VERSION ""

NS_ :

BS_:

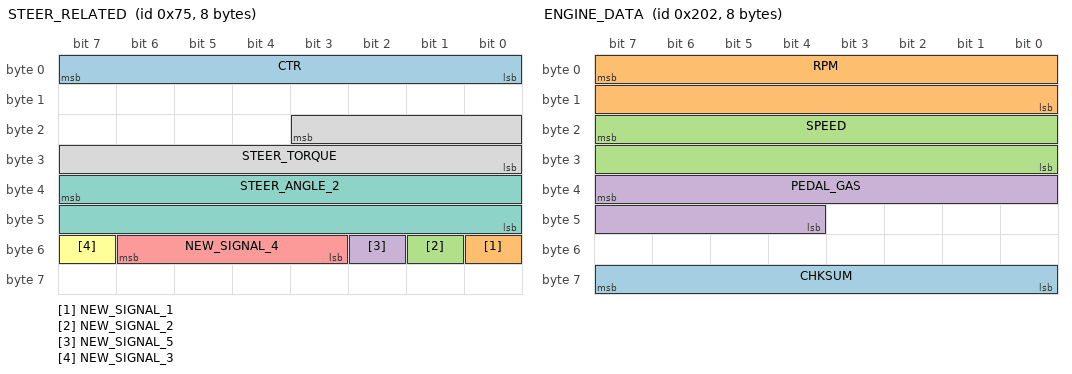
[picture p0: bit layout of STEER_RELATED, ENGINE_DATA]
BO_ 117 STEER_RELATED: 8 XXX
 SG_ CTR : 7|8@0+ (1,0) [0|255] "" XXX
 SG_ NEW_SIGNAL_1 : 48|1@0+ (1,0) [0|1] "" XXX
 SG_ NEW_SIGNAL_2 : 49|1@0+ (1,0) [0|1] "" XXX
 SG_ NEW_SIGNAL_5 : 50|1@0+ (1,0) [0|1] "" XXX
 SG_ NEW_SIGNAL_4 : 54|4@0+ (1,0) [0|31] "" XXX
 SG_ NEW_SIGNAL_3 : 55|1@0+ (1,0) [0|63] "" XXX
 SG_ STEER_ANGLE_2 : 39|16@0+ (0.1,-1800) [0|131071] "" XXX
 SG_ STEER_TORQUE : 19|12@0+ (1,-2000) [0|255] "" XXX

BO_ 118 RPM_RELATED: 8 XXX
 SG_ CTR : 7|8@0+ (1,0) [0|127] "" XXX
 SG_ NEW_SIGNAL_2 : 19|12@0+ (1,0) [0|4095] "" XXX

BO_ 514 ENGINE_DATA: 8 XXX
 SG_ CHKSUM : 63|8@0+ (1,0) [0|127] "" XXX
 SG_ RPM : 7|16@0+ (0.25,0) [0|8500] "rpm" XXX
 SG_ SPEED : 23|16@0+ (0.01,0) [0|32767] "kph" XXX
 SG_ PEDAL_GAS : 39|12@0+ (1,0) [0|255] "%" XXX

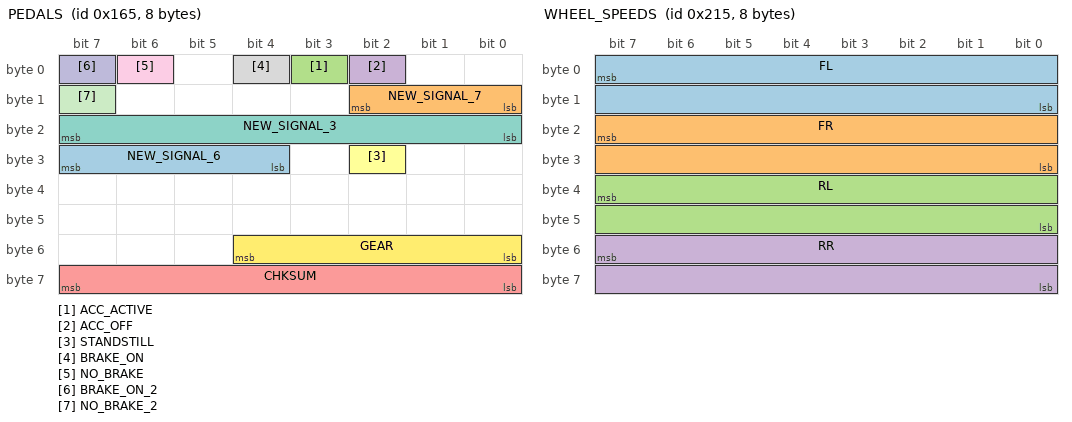
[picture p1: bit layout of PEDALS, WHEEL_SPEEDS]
BO_ 357 PEDALS: 8 XXX
 SG_ NEW_SIGNAL_6 : 31|4@0+ (1,0) [0|1] "" XXX
 SG_ NEW_SIGNAL_7 : 8|3@1+ (1,0) [0|7] "" XXX
 SG_ ACC_ACTIVE : 3|1@0+ (1,0) [0|1] "" XXX
 SG_ ACC_OFF : 2|1@1+ (1,0) [0|15] "" XXX
 SG_ CHKSUM : 63|8@0+ (1,0) [0|15] "" XXX
 SG_ STANDSTILL : 26|1@0+ (1,0) [0|16777215] "" XXX
 SG_ NEW_SIGNAL_3 : 23|8@0+ (1,0) [0|3] "" XXX
 SG_ BRAKE_ON : 4|1@0+ (1,0) [0|1] "" XXX
 SG_ NO_BRAKE : 6|1@0+ (1,0) [0|7] "" XXX
 SG_ BRAKE_ON_2 : 7|1@1+ (1,0) [0|255] "" XXX
 SG_ NO_BRAKE_2 : 15|1@0+ (1,0) [0|7] "" XXX
 SG_ GEAR : 48|5@1+ (1,0) [0|255] "" XXX

BO_ 533 WHEEL_SPEEDS: 8 XXX
 SG_ FL : 7|16@0+ (0.01,-100) [0|16383] "kph" XXX
 SG_ FR : 23|16@0+ (0.01,-100) [0|65535] "kph" XXX
 SG_ RL : 39|16@0+ (0.01,-100) [0|15] "kph" XXX
 SG_ RR : 55|16@0+ (0.01,-100) [0|65535] "kph" XXX

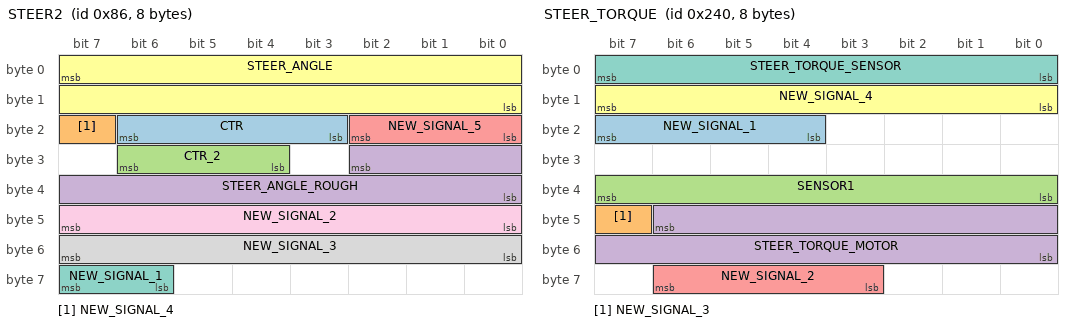
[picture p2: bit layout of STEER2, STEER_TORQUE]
BO_ 134 STEER2: 8 XXX
 SG_ CTR : 22|4@0+ (1,0) [0|7] "" XXX
 SG_ NEW_SIGNAL_4 : 23|1@0+ (1,0) [0|1] "" XXX
 SG_ CTR_2 : 28|3@1+ (1,0) [0|7] "" XXX
 SG_ STEER_ANGLE_ROUGH : 26|11@0+ (1,-1000) [0|15] "" XXX
 SG_ NEW_SIGNAL_5 : 18|3@0+ (1,0) [0|1] "" XXX
 SG_ STEER_ANGLE : 7|16@0+ (0.1,-1600) [-500|500] "deg" XXX
 SG_ NEW_SIGNAL_1 : 63|2@0+ (1,0) [0|3] "" XXX
 SG_ NEW_SIGNAL_3 : 55|8@0+ (1,0) [0|255] "" XXX
 SG_ NEW_SIGNAL_2 : 47|8@0+ (1,0) [0|7] "" XXX

BO_ 576 STEER_TORQUE: 8 XXX
 SG_ NEW_SIGNAL_1 : 23|4@0+ (1,0) [0|255] "" XXX
 SG_ NEW_SIGNAL_3 : 47|1@0+ (1,0) [0|1] "" XXX
 SG_ SENSOR1 : 39|8@0+ (1,-128) [0|127] "" XXX
 SG_ STEER_TORQUE_MOTOR : 46|15@0- (0.1,0) [-3000|3000] "tbd" XXX
 SG_ NEW_SIGNAL_2 : 62|4@0+ (1,0) [0|31] "" XXX
 SG_ NEW_SIGNAL_4 : 15|8@0+ (1,0) [0|127] "" XXX
 SG_ STEER_TORQUE_SENSOR : 7|8@0+ (1,-127) [-85|85] "" XXX

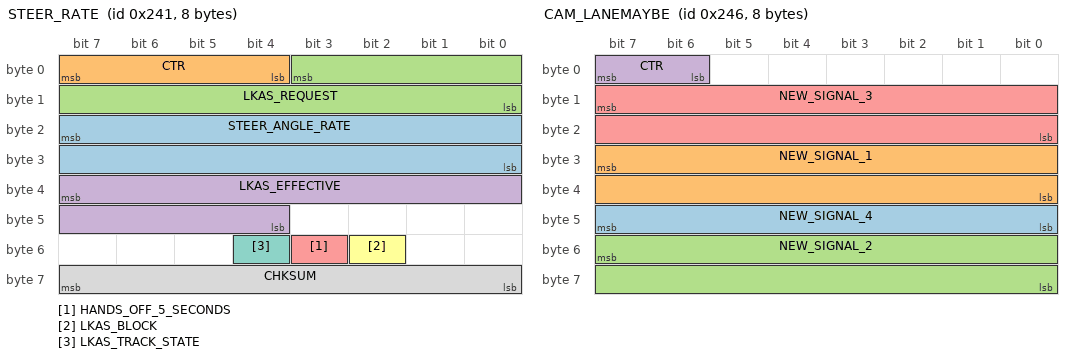
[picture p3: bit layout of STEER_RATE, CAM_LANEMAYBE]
BO_ 577 STEER_RATE: 8 XXX
 SG_ STEER_ANGLE_RATE : 23|16@0+ (0.25,-8192) [0|1] "deg/s" XXX
 SG_ CTR : 7|4@0+ (1,0) [0|15] "" XXX
 SG_ LKAS_REQUEST : 3|12@0+ (1,-2048) [0|15] "" XXX
 SG_ LKAS_EFFECTIVE : 39|12@0+ (1,-2048) [0|255] "" XXX
 SG_ HANDS_OFF_5_SECONDS : 51|1@0+ (1,0) [0|1] "" XXX
 SG_ LKAS_BLOCK : 50|1@1+ (1,0) [0|3] "" XXX
 SG_ LKAS_TRACK_STATE : 52|1@0+ (1,0) [0|3] "" XXX
 SG_ CHKSUM : 63|8@0+ (1,0) [0|255] "" XXX

BO_ 582 CAM_LANEMAYBE: 8 XXX
 SG_ NEW_SIGNAL_4 : 40|8@1+ (1,0) [0|127] "" XXX
 SG_ NEW_SIGNAL_1 : 31|16@0- (1,0) [0|65535] "" XXX
 SG_ NEW_SIGNAL_2 : 55|16@0+ (1,0) [0|65535] "" XXX
 SG_ CTR : 7|2@0+ (1,0) [0|3] "" XXX
 SG_ NEW_SIGNAL_3 : 15|16@0+ (1,0) [0|65535] "" XXX

BO_ 541 CAM_EMPTY: 8 XXX

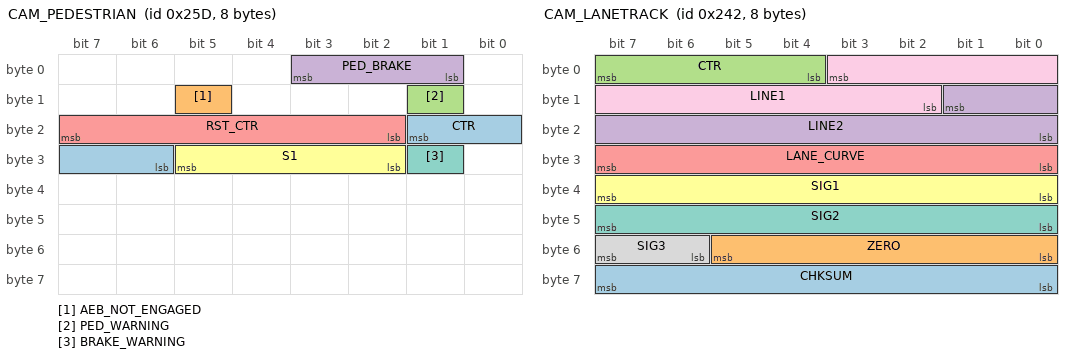
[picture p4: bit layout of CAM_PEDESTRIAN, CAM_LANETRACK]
BO_ 605 CAM_PEDESTRIAN: 8 XXX
 SG_ CTR : 17|4@0+ (1,0) [0|255] "" XXX
 SG_ AEB_NOT_ENGAGED : 13|1@0+ (1,0) [0|1] "" XXX
 SG_ PED_WARNING : 9|1@0+ (1,0) [0|255] "" XXX
 SG_ PED_BRAKE : 3|3@0+ (1,0) [0|7] "" XXX
 SG_ RST_CTR : 23|6@0+ (1,0) [0|63] "" XXX
 SG_ S1 : 29|4@0+ (1,0) [0|31] "" XXX
 SG_ BRAKE_WARNING : 25|1@0+ (1,0) [0|1] "" XXX

BO_ 578 CAM_LANETRACK: 8 XXX
 SG_ CHKSUM : 63|8@0+ (1,0) [0|255] "" XXX
 SG_ ZERO : 53|6@0+ (1,0) [0|63] "" XXX
 SG_ CTR : 7|4@0+ (1,0) [0|15] "" XXX
 SG_ LINE2 : 9|10@0+ (1,-686) [0|255] "" XXX
 SG_ LANE_CURVE : 31|8@0+ (1,-127) [0|255] "" XXX
 SG_ SIG1 : 39|8@0+ (1,-128) [0|255] "" XXX
 SG_ SIG2 : 47|8@0+ (1,0) [0|255] "" XXX
 SG_ SIG3 : 55|2@0+ (1,0) [0|3] "" XXX
 SG_ LINE1 : 3|10@0+ (1,-686) [0|1] "" XXX

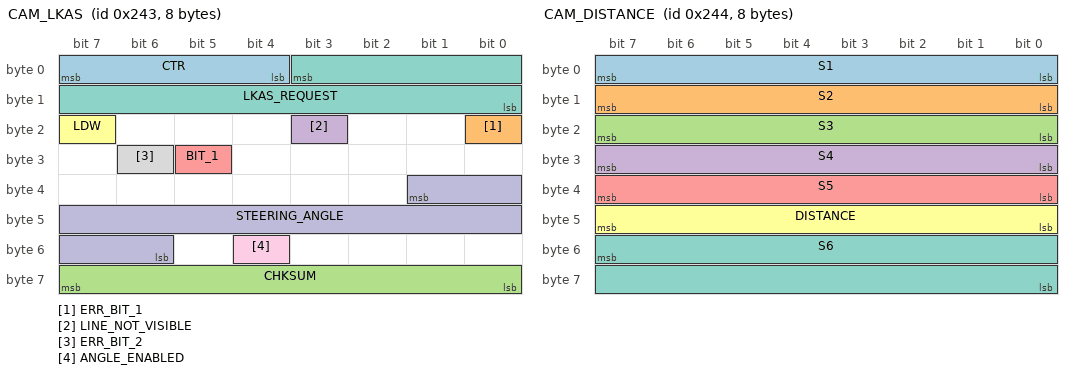
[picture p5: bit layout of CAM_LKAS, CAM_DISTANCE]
BO_ 579 CAM_LKAS: 8 XXX
 SG_ CTR : 7|4@0+ (1,0) [0|15] "" XXX
 SG_ ERR_BIT_1 : 16|1@0+ (1,0) [0|1] "" XXX
 SG_ CHKSUM : 63|8@0+ (1,0) [0|15] "" XXX
 SG_ LINE_NOT_VISIBLE : 19|1@0+ (1,0) [0|1] "" XXX
 SG_ BIT_1 : 29|1@0+ (1,0) [0|1] "" XXX
 SG_ LDW : 23|1@0+ (1,0) [0|1] "" XXX
 SG_ LKAS_REQUEST : 3|12@0+ (1,-2048) [0|2048] "" XXX
 SG_ ERR_BIT_2 : 30|1@0+ (1,0) [0|1] "" XXX
 SG_ ANGLE_ENABLED : 52|1@0+ (1,0) [0|1] "" XXX
 SG_ STEERING_ANGLE : 33|12@0+ (1,-2048) [-2048|2047] "" XXX

BO_ 580 CAM_DISTANCE: 8 XXX
 SG_ S1 : 0|8@1+ (1,0) [0|127] "" XXX
 SG_ S2 : 15|8@0+ (1,0) [0|1] "" XXX
 SG_ S3 : 16|8@1+ (1,0) [0|3] "" XXX
 SG_ S4 : 24|8@1+ (1,0) [0|31] "" XXX
 SG_ S5 : 32|8@1+ (1,0) [0|255] "" XXX
 SG_ DISTANCE : 47|8@0+ (1,0) [0|65535] "" XXX
 SG_ S6 : 55|16@0+ (1,0) [0|255] "" XXX

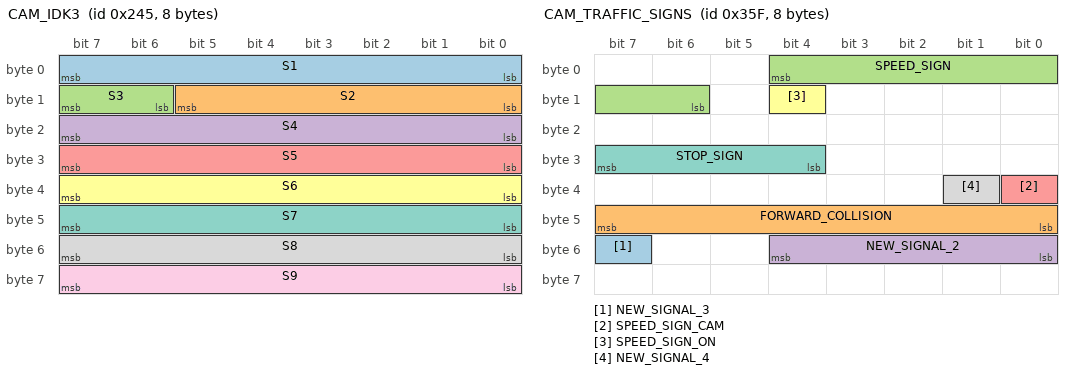
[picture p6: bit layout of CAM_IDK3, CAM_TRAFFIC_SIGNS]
BO_ 581 CAM_IDK3: 8 XXX
 SG_ S1 : 0|8@1+ (1,0) [0|15] "" XXX
 SG_ S2 : 8|6@1+ (1,0) [0|255] "" XXX
 SG_ S3 : 15|2@0+ (1,0) [0|3] "" XXX
 SG_ S4 : 16|8@1+ (1,0) [0|15] "" XXX
 SG_ S5 : 24|8@1+ (1,0) [0|255] "" XXX
 SG_ S6 : 32|8@1+ (1,0) [0|255] "" XXX
 SG_ S7 : 40|8@1+ (1,0) [0|3] "" XXX
 SG_ S8 : 48|8@1+ (1,0) [0|255] "" XXX
 SG_ S9 : 56|8@1+ (1,0) [0|255] "" XXX

BO_ 863 CAM_TRAFFIC_SIGNS: 8 XXX
 SG_ NEW_SIGNAL_3 : 55|1@0+ (1,0) [0|127] "" XXX
 SG_ FORWARD_COLLISION : 40|8@1+ (1,0) [0|7] "" XXX
 SG_ SPEED_SIGN : 4|7@0+ (1,0) [0|15] "" XXX
 SG_ NEW_SIGNAL_2 : 52|5@0+ (1,0) [0|31] "" XXX
 SG_ SPEED_SIGN_CAM : 32|1@0+ (1,0) [0|32767] "" XXX
 SG_ SPEED_SIGN_ON : 12|1@0+ (1,0) [0|3] "" XXX
 SG_ STOP_SIGN : 31|4@0+ (1,0) [0|1] "" XXX
 SG_ NEW_SIGNAL_4 : 33|1@0+ (1,0) [0|1] "" XXX

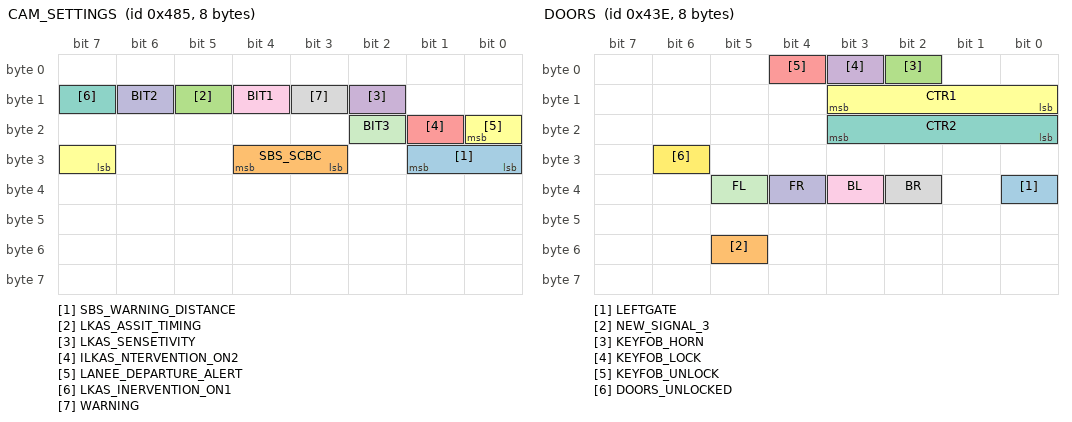
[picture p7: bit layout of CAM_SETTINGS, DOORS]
BO_ 1157 CAM_SETTINGS: 8 XXX
 SG_ SBS_WARNING_DISTANCE : 25|2@0+ (1,0) [0|127] "" XXX
 SG_ SBS_SCBC : 28|2@0+ (1,0) [0|7] "" XXX
 SG_ LKAS_ASSIT_TIMING : 13|1@0+ (1,0) [0|1] "" XXX
 SG_ LKAS_SENSETIVITY : 10|1@0+ (1,0) [0|1] "" XXX
 SG_ ILKAS_NTERVENTION_ON2 : 17|1@0+ (1,0) [0|255] "" XXX
 SG_ LANEE_DEPARTURE_ALERT : 16|2@0+ (1,0) [0|1] "" XXX
 SG_ LKAS_INERVENTION_ON1 : 15|1@0+ (1,0) [0|1] "" XXX
 SG_ WARNING : 11|1@0+ (1,0) [0|1] "" XXX
 SG_ BIT1 : 12|1@0+ (1,0) [0|7] "" XXX
 SG_ BIT2 : 14|1@0+ (1,0) [0|1] "" XXX
 SG_ BIT3 : 18|1@0+ (1,0) [0|1] "" XXX

BO_ 1160 CAM_Empty3: 8 XXX
 SG_ NEW_SIGNAL_1 : 47|24@0+ (1,0) [0|16777215] "" XXX

BO_ 1088 CAM_LANEINFO: 8 XXX
 SG_ BIT3 : 62|1@0+ (1,0) [0|3] "" XXX
 SG_ HANDS_ON_STEER_WARN_2 : 59|1@0+ (1,0) [0|1] "" XXX
 SG_ HANDS_ON_STEER_WARN : 56|1@0+ (1,0) [0|3] "" XXX
 SG_ S1_HBEAM : 54|1@0+ (1,0) [0|31] "" XXX
 SG_ S1 : 52|1@0+ (1,0) [0|1] "" XXX
 SG_ HANDS_WARN_3_BITS : 51|3@0+ (1,0) [0|7] "" XXX
 SG_ ERR_BIT : 40|1@0+ (1,0) [0|1] "" XXX
 SG_ NO_ERR_BIT : 14|1@0+ (1,0) [0|1] "" XXX
 SG_ BIT2 : 13|1@0+ (1,0) [0|15] "" XXX
 SG_ LANE_LINES : 10|3@0+ (1,0) [0|3] "" XXX
 SG_ BIT1 : 6|1@0+ (1,0) [0|65535] "" XXX
 SG_ LINE_NOT_VISIBLE : 1|1@0+ (1,0) [0|1] "" XXX
 SG_ LINE_VISIBLE : 0|1@0+ (1,0) [0|3] "" XXX
 SG_ LDW_WARN_RL : 58|1@0+ (1,0) [0|1] "" XXX
 SG_ LDW_WARN_LL : 57|1@0+ (1,0) [0|1] "" XXX
 SG_ TJA : 38|3@0+ (1,0) [0|7] "" XXX
 SG_ TJA_TRANSITION : 27|2@0+ (1,0) [0|63] "" XXX

BO_ 1479 NEW_MSG_470: 8 XXX

BO_ 1456 NEW_MSG_300: 8 XXX

BO_ 1446 NEW_MSG_a600: 8 XXX

BO_ 1416 MSG_18: 8 XXX

BO_ 1086 DOORS: 8 XXX
 SG_ LEFTGATE : 32|1@0+ (1,0) [0|1] "" XXX
 SG_ NEW_SIGNAL_3 : 53|1@0+ (1,0) [0|255] "" XXX
 SG_ KEYFOB_HORN : 2|1@0+ (1,0) [0|1] "" XXX
 SG_ KEYFOB_LOCK : 3|1@0+ (1,0) [0|1] "" XXX
 SG_ KEYFOB_UNLOCK : 4|1@0+ (1,0) [0|1] "" XXX
 SG_ CTR1 : 8|4@1+ (1,0) [0|3] "" XXX
 SG_ CTR2 : 16|4@1+ (1,0) [0|15] "" XXX
 SG_ BR : 34|1@0+ (1,0) [0|1] "" XXX
 SG_ BL : 35|1@0+ (1,0) [0|1] "" XXX
 SG_ FR : 36|1@0+ (1,0) [0|1] "" XXX
 SG_ FL : 37|1@0+ (1,0) [0|255] "" XXX
 SG_ DOORS_UNLOCKED : 30|1@0+ (1,0) [0|255] "" XXX

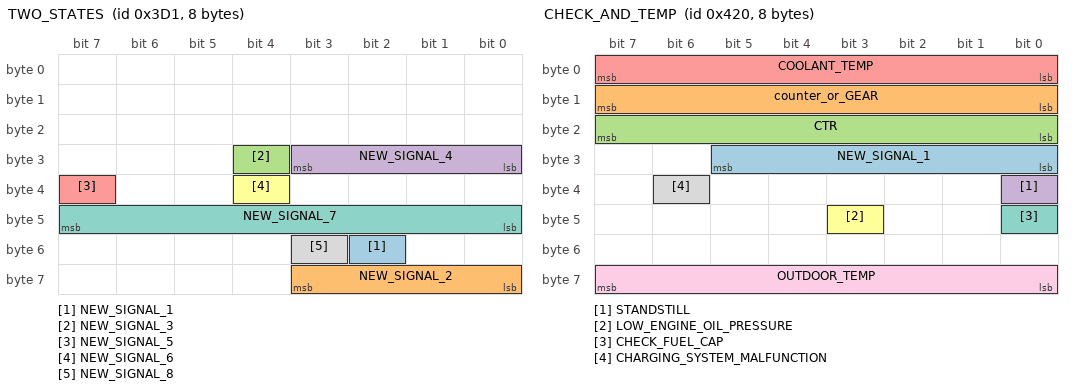
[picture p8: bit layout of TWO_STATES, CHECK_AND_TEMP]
BO_ 977 TWO_STATES: 8 XXX
 SG_ NEW_SIGNAL_1 : 50|1@1+ (1,0) [0|7] "" XXX
 SG_ NEW_SIGNAL_2 : 56|4@1+ (1,0) [0|7] "" XXX
 SG_ NEW_SIGNAL_3 : 28|1@0+ (1,0) [0|255] "" XXX
 SG_ NEW_SIGNAL_4 : 24|4@1+ (1,0) [0|3] "" XXX
 SG_ NEW_SIGNAL_5 : 39|1@0+ (1,0) [0|1] "" XXX
 SG_ NEW_SIGNAL_6 : 36|1@0+ (1,0) [0|1] "" XXX
 SG_ NEW_SIGNAL_7 : 47|8@0+ (1,0) [0|1] "" XXX
 SG_ NEW_SIGNAL_8 : 51|1@0+ (1,0) [0|1] "" XXX

BO_ 1085 MSG_12: 8 XXX
 SG_ NEW_SIGNAL_3 : 36|1@0+ (1,0) [0|255] "" XXX
 SG_ NEW_SIGNAL_1 : 16|8@1+ (1,0) [0|15] "" XXX
 SG_ NEW_SIGNAL_2 : 48|8@1+ (1,0) [0|65535] "" XXX
 SG_ NEW_SIGNAL_4 : 31|1@0+ (1,0) [0|255] "" XXX
 SG_ NEW_SIGNAL_5 : 24|1@0+ (1,0) [0|127] "" XXX
 SG_ NEW_SIGNAL_6 : 40|3@1+ (1,0) [0|7] "" XXX

BO_ 159 MSG_11: 8 XXX
 SG_ NEW_SIGNAL_1 : 50|4@1+ (1,0) [0|15] "" XXX
 SG_ INCREASEING : 39|8@0+ (1,0) [0|255] "" XXX

BO_ 1278 NEW_MSG_3: 8 XXX
 SG_ NEW_SIGNAL_2 : 23|8@0+ (1,0) [0|255] "" XXX
 SG_ NEW_SIGNAL_3 : 31|8@0+ (1,0) [0|255] "" XXX
 SG_ NEW_SIGNAL_4 : 39|8@0+ (1,0) [0|255] "" XXX
 SG_ NEW_SIGNAL_5 : 47|8@0+ (1,0) [0|255] "" XXX
 SG_ NEW_SIGNAL_6 : 55|8@0+ (1,0) [0|255] "" XXX
 SG_ NEW_SIGNAL_7 : 63|8@0+ (1,0) [0|255] "" XXX
 SG_ MILAGE_MAYBE : 7|16@0+ (1,0) [0|255] "" XXX

BO_ 1277 NEW_MSG_10: 8 XXX
 SG_ NEW_SIGNAL_3 : 31|8@0+ (1,0) [0|255] "" XXX
 SG_ NEW_SIGNAL_2 : 15|8@0+ (1,0) [0|255] "" XXX
 SG_ counter : 7|8@0+ (1,0) [0|255] "" XXX

BO_ 1275 2017_5: 8 XXX
 SG_ counter : 4|5@0+ (1,0) [0|255] "" XXX

BO_ 1274 NEW_MSG_12: 8 XXX
 SG_ NEW_SIGNAL_1 : 24|4@1+ (1,0) [0|15] "" XXX
 SG_ CTR : 55|4@0+ (1,0) [0|63] "" XXX
 SG_ NEW_SIGNAL_2 : 35|1@0+ (1,0) [0|255] "" XXX
 SG_ NEW_SIGNAL_3 : 32|3@1+ (1,0) [0|3] "" XXX
 SG_ NEW_SIGNAL_4 : 48|4@1+ (1,0) [0|7] "" XXX

BO_ 1180 last_byte_roughRPM: 8 XXX
 SG_ NEW_SIGNAL_1 : 63|8@0+ (1,0) [0|255] "" XXX

BO_ 1078 HVAC: 8 XXX
 SG_ NEW_SIGNAL_1 : 2|1@0+ (1,0) [0|1] "" XXX
 SG_ NEW_SIGNAL_2 : 8|1@0+ (1,0) [0|255] "" XXX
 SG_ NEW_SIGNAL_3 : 23|1@0+ (1,0) [0|65535] "" XXX
 SG_ NEW_SIGNAL_4 : 56|5@0+ (1,0) [0|255] "" XXX

BO_ 1056 CHECK_AND_TEMP: 8 XXX
 SG_ NEW_SIGNAL_1 : 29|6@0+ (1,0) [0|255] "" XXX
 SG_ counter_or_GEAR : 15|8@0+ (1,0) [0|255] "" XXX
 SG_ CTR : 23|8@0+ (1,0) [0|255] "" XXX
 SG_ STANDSTILL : 32|1@0+ (1,0) [0|255] "" XXX
 SG_ COOLANT_TEMP : 7|8@0+ (1,0) [0|255] "" XXX
 SG_ LOW_ENGINE_OIL_PRESSURE : 43|1@0+ (1,0) [0|1] "" XXX
 SG_ CHECK_FUEL_CAP : 40|1@0+ (1,0) [0|1] "" XXX
 SG_ CHARGING_SYSTEM_MALFUNCTION : 38|1@0+ (1,0) [0|1] "" XXX
 SG_ OUTDOOR_TEMP : 63|8@0+ (0.25,-63) [0|255] "cel" XXX

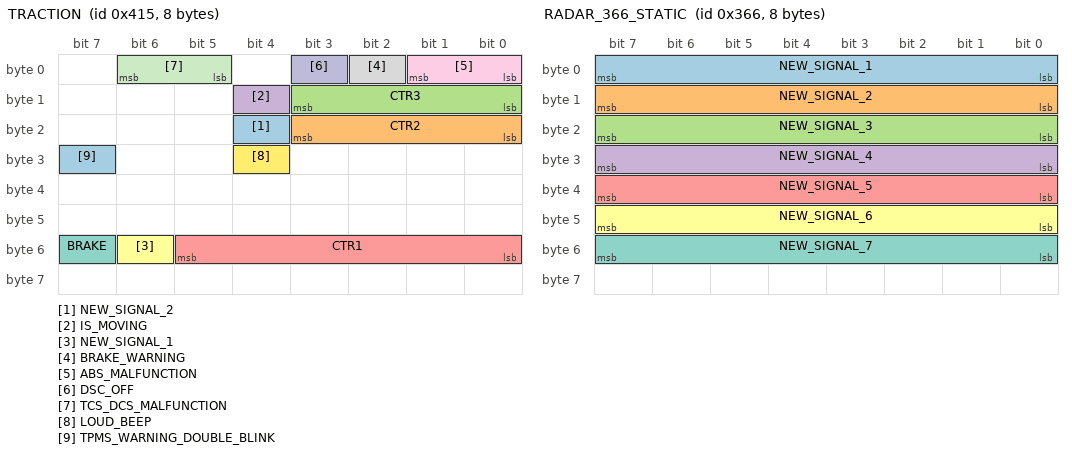
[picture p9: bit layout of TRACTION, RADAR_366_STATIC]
BO_ 1045 TRACTION: 8 XXX
 SG_ NEW_SIGNAL_2 : 20|1@0+ (1,0) [0|3] "" XXX
 SG_ CTR2 : 19|4@0+ (1,0) [0|31] "" XXX
 SG_ CTR3 : 8|4@1+ (1,0) [0|15] "" XXX
 SG_ IS_MOVING : 12|1@0+ (1,0) [0|3] "" XXX
 SG_ CTR1 : 53|6@0+ (1,0) [0|255] "" XXX
 SG_ NEW_SIGNAL_1 : 54|1@0+ (1,0) [0|1] "" XXX
 SG_ BRAKE : 55|1@0+ (1,0) [0|1] "" XXX
 SG_ BRAKE_WARNING : 2|1@0+ (1,0) [0|1] "" XXX
 SG_ ABS_MALFUNCTION : 1|2@0+ (1,0) [0|3] "" XXX
 SG_ DSC_OFF : 3|1@0+ (1,0) [0|1] "" XXX
 SG_ TCS_DCS_MALFUNCTION : 6|2@0+ (1,0) [0|3] "" XXX
 SG_ LOUD_BEEP : 28|1@0+ (1,0) [0|1] "" XXX
 SG_ TPMS_WARNING_DOUBLE_BLINK : 31|1@0+ (1,0) [0|1] "" XXX

BO_ 1034 MSG_07: 8 XXX
 SG_ NEW_SIGNAL_1 : 6|3@0+ (1,0) [0|3] "" XXX
 SG_ NEW_SIGNAL_2 : 0|4@1+ (1,0) [0|3] "" XXX
 SG_ NEW_SIGNAL_3 : 15|4@0+ (1,0) [0|15] "" XXX
 SG_ NEW_SIGNAL_4 : 63|8@0+ (1,0) [0|255] "" XXX
 SG_ NEW_SIGNAL_5 : 23|8@0+ (1,0) [0|255] "" XXX
 SG_ NEW_SIGNAL_6 : 55|8@0+ (1,0) [0|255] "" XXX
 SG_ NEW_SIGNAL_7 : 47|8@0+ (1,0) [0|255] "" XXX
 SG_ NEW_SIGNAL_8 : 39|8@0+ (1,0) [0|255] "" XXX
 SG_ NEW_SIGNAL_9 : 31|8@0+ (1,0) [0|255] "" XXX

BO_ 870 RADAR_366_STATIC: 8 XXX
 SG_ NEW_SIGNAL_1 : 7|8@0+ (1,0) [0|255] "" XXX
 SG_ NEW_SIGNAL_2 : 15|8@0+ (1,0) [0|255] "" XXX
 SG_ NEW_SIGNAL_3 : 23|8@0+ (1,0) [0|255] "" XXX
 SG_ NEW_SIGNAL_4 : 31|8@0+ (1,0) [0|255] "" XXX
 SG_ NEW_SIGNAL_5 : 39|8@0+ (1,0) [0|255] "" XXX
 SG_ NEW_SIGNAL_6 : 47|8@0+ (1,0) [0|255] "" XXX
 SG_ NEW_SIGNAL_7 : 55|8@0+ (1,0) [0|255] "" XXX

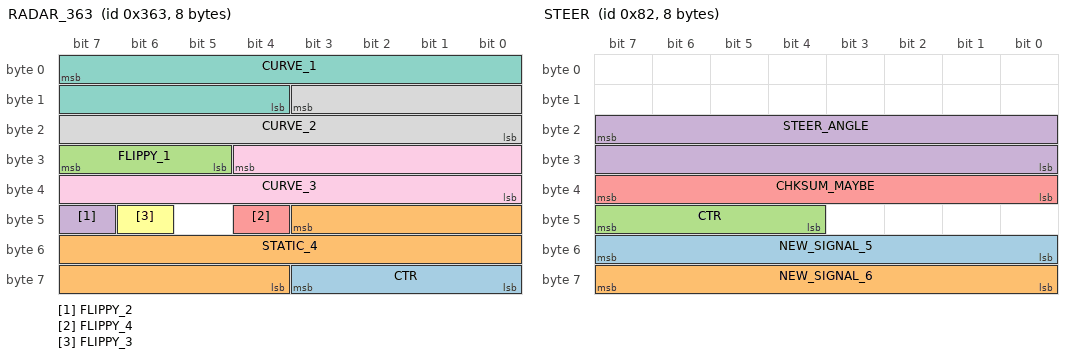
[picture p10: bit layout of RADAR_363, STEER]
BO_ 867 RADAR_363: 8 XXX
 SG_ CTR : 59|4@0+ (1,0) [0|255] "" XXX
 SG_ STATIC_4 : 43|16@0+ (1,0) [0|255] "" XXX
 SG_ FLIPPY_1 : 31|3@0+ (1,0) [0|7] "" XXX
 SG_ FLIPPY_2 : 47|1@0+ (1,0) [0|15] "" XXX
 SG_ FLIPPY_4 : 44|1@0+ (1,0) [0|3] "" XXX
 SG_ FLIPPY_3 : 46|1@0+ (1,0) [0|3] "" XXX
 SG_ CURVE_1 : 7|12@0+ (1,0) [0|255] "" XXX
 SG_ CURVE_2 : 11|12@0+ (1,0) [0|255] "" XXX
 SG_ CURVE_3 : 28|13@0+ (1,0) [0|255] "" XXX

BO_ 130 STEER: 8 XXX
 SG_ NEW_SIGNAL_5 : 55|8@0+ (1,0) [0|255] "" XXX
 SG_ NEW_SIGNAL_6 : 63|8@0+ (1,0) [0|255] "" XXX
 SG_ CTR : 47|4@0+ (1,0) [0|255] "" XXX
 SG_ STEER_ANGLE : 23|16@0+ (0.05,-1600) [500|-500] "deg" XXX
 SG_ CHKSUM_MAYBE : 39|8@0+ (1,0) [0|255] "" XXX

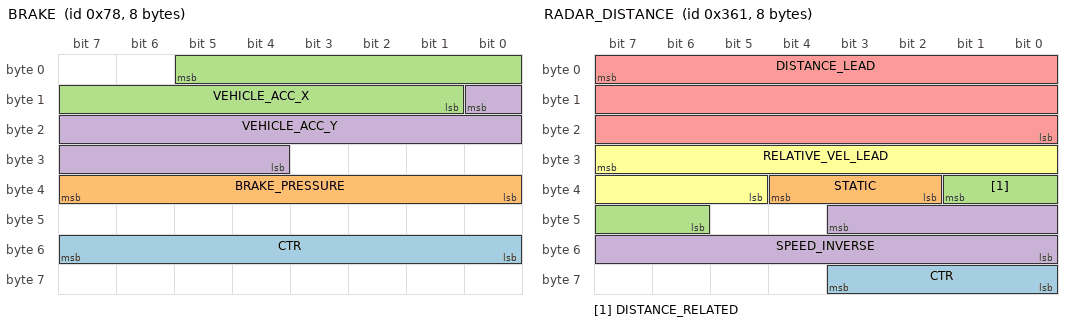
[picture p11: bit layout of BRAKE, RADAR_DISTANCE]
BO_ 120 BRAKE: 8 XXX
 SG_ CTR : 55|8@0+ (1,0) [0|255] "" XXX
 SG_ BRAKE_PRESSURE : 39|8@0+ (1,0) [0|255] "" XXX
 SG_ VEHICLE_ACC_X : 5|13@0+ (0.01,-40) [-40|40] "m/s^2" XXX
 SG_ VEHICLE_ACC_Y : 8|13@0+ (0.001,-4.096) [-4.096|4.096] "m/s^2" XXX

BO_ 304 GEAR_RELATED: 8 XXX
 SG_ NEW_SIGNAL_1 : 55|8@0+ (1,0) [0|255] "" XXX
 SG_ NEW_SIGNAL_2 : 47|8@0+ (1,0) [0|255] "" XXX

BO_ 865 RADAR_DISTANCE: 8 XXX
 SG_ CTR : 56|4@1+ (1,0) [0|15] "" XXX
 SG_ STATIC : 36|3@0+ (1,0) [0|31] "" XXX
 SG_ DISTANCE_RELATED : 33|4@0+ (1,0) [0|3] "" XXX
 SG_ SPEED_INVERSE : 43|12@0- (-0.225,0) [0|255] "kph" XXX
 SG_ DISTANCE_LEAD : 7|24@0+ (1,0) [0|31] "" XXX
 SG_ RELATIVE_VEL_LEAD : 31|11@0- (1,0) [0|255] "" XXX

BO_ 836 NEW_MSG_19: 8 XXX
 SG_ CTR : 48|4@1+ (1,0) [0|15] "" XXX
 SG_ CTR2 : 63|8@0+ (1,0) [0|255] "" XXX

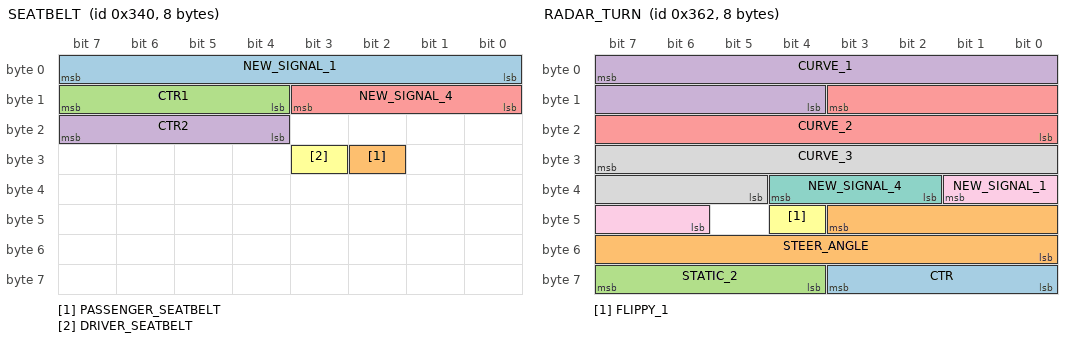
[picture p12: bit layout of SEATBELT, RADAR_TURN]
BO_ 832 SEATBELT: 8 XXX
 SG_ NEW_SIGNAL_1 : 7|8@0+ (1,0) [0|255] "" XXX
 SG_ PASSENGER_SEATBELT : 26|1@1+ (1,0) [0|7] "" XXX
 SG_ CTR1 : 15|4@0+ (1,0) [0|15] "" XXX
 SG_ CTR2 : 23|4@0+ (1,0) [0|255] "" XXX
 SG_ NEW_SIGNAL_4 : 8|4@1+ (1,0) [0|3] "" XXX
 SG_ DRIVER_SEATBELT : 27|1@0+ (1,0) [0|1] "" XXX

BO_ 866 RADAR_TURN: 8 XXX
 SG_ CTR : 59|4@0+ (1,0) [0|15] "" XXX
 SG_ STEER_ANGLE : 43|12@0+ (-1,2048) [0|7] "" XXX
 SG_ STATIC_2 : 63|4@0+ (1,0) [0|15] "" XXX
 SG_ CURVE_1 : 7|12@0+ (1,0) [0|131071] "" XXX
 SG_ CURVE_2 : 11|12@0- (1,0) [0|127] "" XXX
 SG_ FLIPPY_1 : 44|1@0+ (1,0) [0|15] "" XXX
 SG_ NEW_SIGNAL_4 : 34|3@1+ (1,0) [0|3] "" XXX
 SG_ CURVE_3 : 31|11@0- (1,0) [0|63] "" XXX
 SG_ NEW_SIGNAL_1 : 33|4@0+ (1,0) [0|3] "" XXX

BO_ 158 MSG_05: 8 XXX
 SG_ NEW_SIGNAL_1 : 23|8@0+ (1,0) [0|15] "" XXX
 SG_ NEW_SIGNAL_2 : 47|8@0+ (1,0) [0|255] "" XXX
 SG_ NEW_SIGNAL_3 : 55|8@0+ (1,0) [0|255] "" XXX

BO_ 157 CRZ_BTNS: 8 XXX
 SG_ BIT1 : 16|1@0+ (1,0) [0|1] "" XXX
 SG_ BIT2 : 18|1@0+ (1,0) [0|1] "" XXX
 SG_ BIT3 : 20|1@0+ (1,0) [0|1] "" XXX
 SG_ SET_P_INV : 21|1@0+ (1,0) [0|1] "" XXX
 SG_ CAN_OFF_INV : 17|1@0+ (1,0) [0|1] "" XXX
 SG_ CAN_OFF : 0|1@0+ (1,0) [0|1] "" XXX
 SG_ SET_M_INV : 22|1@0+ (1,0) [0|1] "" XXX
 SG_ SET_M : 5|1@0+ (1,0) [0|1] "" XXX
 SG_ SET_P : 4|1@0+ (1,0) [0|1] "" XXX
 SG_ RES_INV : 19|1@0+ (1,0) [0|1] "" XXX
 SG_ RES : 2|1@0+ (1,0) [0|1] "" XXX
 SG_ DISTANCE_LESS : 7|1@0+ (1,0) [0|1] "" XXX
 SG_ DISTANCE_LESS_INV : 8|1@0+ (1,0) [0|1] "" XXX
 SG_ DISTANCE_MORE : 6|1@0+ (1,0) [0|1] "" XXX
 SG_ DISTANCE_MORE_INV : 23|1@0+ (1,0) [0|1] "" XXX
 SG_ MODE_Y : 13|1@0+ (1,0) [0|1] "" XXX
 SG_ MODE_X : 14|1@0+ (1,0) [0|1] "" XXX
 SG_ MODE_Y_INV : 30|1@0+ (1,0) [0|1] "" XXX
 SG_ MODE_X_INV : 31|1@0+ (1,0) [0|1] "" XXX
 SG_ CTR : 29|4@0+ (1,0) [0|15] "" XXX

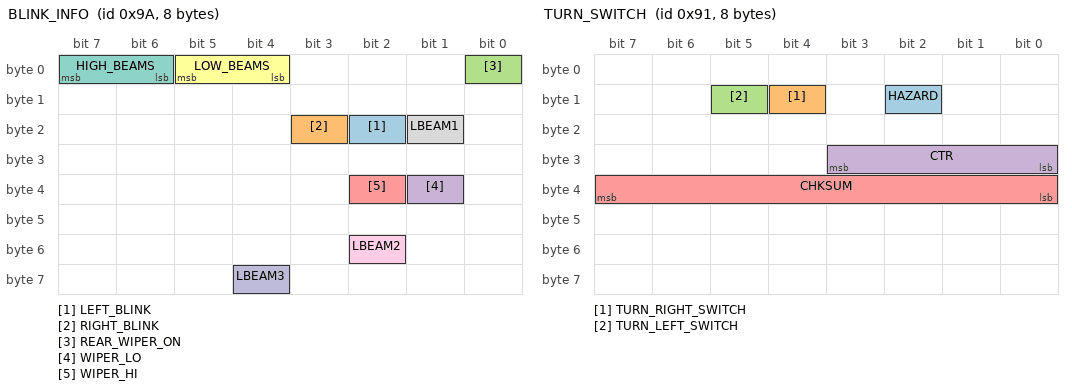
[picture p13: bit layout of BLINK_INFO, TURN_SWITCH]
BO_ 154 BLINK_INFO: 8 XXX
 SG_ LEFT_BLINK : 18|1@1+ (1,0) [0|3] "" XXX
 SG_ RIGHT_BLINK : 19|1@0+ (1,0) [0|255] "" XXX
 SG_ REAR_WIPER_ON : 0|1@0+ (1,0) [0|1] "" XXX
 SG_ WIPER_LO : 33|1@1+ (1,0) [0|31] "" XXX
 SG_ WIPER_HI : 34|1@0+ (1,0) [0|1] "" XXX
 SG_ LOW_BEAMS : 5|2@0+ (1,0) [0|3] "" XXX
 SG_ HIGH_BEAMS : 7|2@0+ (1,0) [0|3] "" XXX
 SG_ LBEAM1 : 17|1@0+ (1,0) [0|1] "" XXX
 SG_ LBEAM2 : 50|1@0+ (1,0) [0|1] "" XXX
 SG_ LBEAM3 : 60|1@0+ (1,0) [0|1] "" XXX

BO_ 145 TURN_SWITCH: 8 XXX
 SG_ HAZARD : 10|1@0+ (1,0) [0|1] "" XXX
 SG_ TURN_RIGHT_SWITCH : 12|1@0+ (1,0) [0|3] "" XXX
 SG_ TURN_LEFT_SWITCH : 13|1@0+ (1,0) [0|255] "" XXX
 SG_ CTR : 27|4@0+ (1,0) [0|255] "" XXX
 SG_ CHKSUM : 39|8@0+ (1,0) [0|15] "" XXX

BO_ 80 MSG_04: 8 XXX
 SG_ NEW_SIGNAL_1 : 25|1@0+ (1,0) [0|1] "" XXX
 SG_ SIGNAL : 24|1@0+ (1,0) [0|1] "" XXX

BO_ 978 MSG_03: 8 XXX
 SG_ NEW_SIGNAL_2 : 15|8@0+ (1,0) [0|255] "" XXX
 SG_ NEW_SIGNAL_3 : 23|8@0+ (1,0) [0|1] "" XXX
 SG_ NEW_SIGNAL_4 : 31|8@0+ (1,0) [0|255] "" XXX
 SG_ NEW_SIGNAL_5 : 39|8@0+ (1,0) [0|255] "" XXX
 SG_ NEW_SIGNAL_6 : 47|8@0+ (1,0) [0|255] "" XXX
 SG_ NEW_SIGNAL_7 : 55|8@0+ (1,0) [0|255] "" XXX
 SG_ NEW_SIGNAL_8 : 63|8@0+ (1,0) [0|255] "" XXX
 SG_ CTR : 1|2@0+ (1,0) [0|255] "" XXX

BO_ 607 NEW_MSG_25: 8 XXX

BO_ 1115 MSG_02: 8 XXX
 SG_ NEW_SIGNAL_2 : 15|8@0+ (1,0) [0|255] "" XXX
 SG_ NEW_SIGNAL_1 : 47|16@0+ (1,0) [0|65535] "" XXX
 SG_ NEW_SIGNAL_3 : 63|1@0+ (1,0) [0|1] "" XXX
 SG_ NEW_SIGNAL_4 : 23|8@0+ (1,0) [0|255] "" XXX
 SG_ NEW_SIGNAL_5 : 31|8@0+ (1,0) [0|255] "" XXX
 SG_ NEW_SIGNAL_6 : 39|8@0+ (1,0) [0|255] "" XXX
 SG_ CTR : 2|3@0+ (1,0) [0|255] "" XXX

BO_ 1067 NEW_MSG_27: 8 XXX
 SG_ NEW_SIGNAL_2 : 3|1@0+ (1,0) [0|1] "" XXX
 SG_ NEW_SIGNAL_4 : 0|1@0+ (1,0) [0|1] "" XXX
 SG_ NEW_SIGNAL_1 : 2|1@0+ (1,0) [0|1] "" XXX
 SG_ NEW_SIGNAL_5 : 1|1@0+ (1,0) [0|1] "" XXX
 SG_ NEW_SIGNAL_3 : 12|1@0+ (1,0) [0|1] "" XXX
 SG_ NEW_SIGNAL_6 : 11|1@1+ (1,0) [0|3] "" XXX
 SG_ NEW_SIGNAL_7 : 10|1@0+ (1,0) [0|1] "" XXX
 SG_ NEW_SIGNAL_8 : 9|1@0+ (1,0) [0|1] "" XXX
 SG_ NEW_SIGNAL_9 : 8|1@0+ (1,0) [0|1] "" XXX

BO_ 358 NEW_MSG_28: 8 XXX

BO_ 608 NEW_MSG_29: 8 XXX
 SG_ NEW_SIGNAL_1 : 8|5@1+ (1,0) [0|7] "" XXX

BO_ 606 SPEED_TBD: 8 XXX
 SG_ SPEED_TBD : 7|12@0+ (1,0) [0|255] "" XXX
 SG_ NEW_SIGNAL_1 : 23|12@0- (1,0) [0|65535] "" XXX

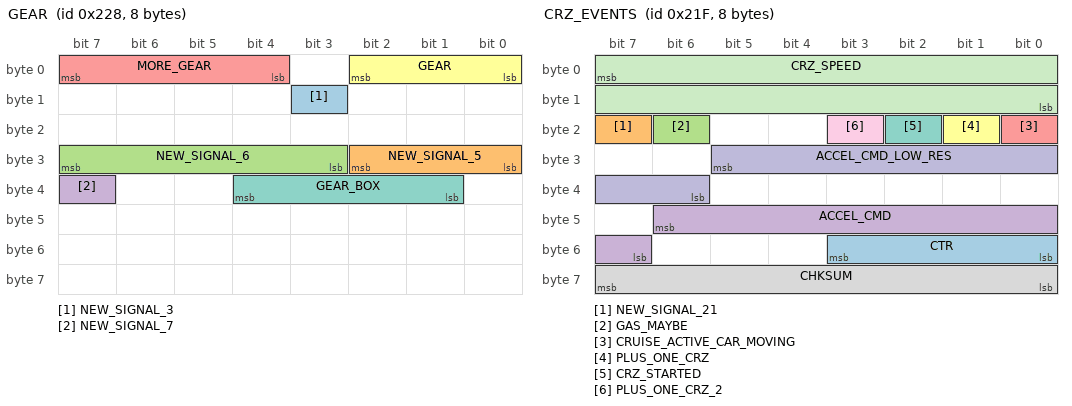
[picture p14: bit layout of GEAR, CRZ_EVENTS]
BO_ 552 GEAR: 8 XXX
 SG_ NEW_SIGNAL_3 : 11|1@0+ (1,0) [0|1] "" XXX
 SG_ NEW_SIGNAL_5 : 26|3@0+ (1,0) [0|255] "" XXX
 SG_ NEW_SIGNAL_6 : 31|5@0+ (1,0) [0|31] "" XXX
 SG_ NEW_SIGNAL_7 : 39|1@0+ (1,0) [0|255] "" XXX
 SG_ MORE_GEAR : 7|4@0+ (1,0) [0|15] "" XXX
 SG_ GEAR : 2|3@0+ (1,0) [0|7] "" XXX
 SG_ GEAR_BOX : 36|4@0+ (1,0) [0|15] "" XXX

BO_ 543 CRZ_EVENTS: 8 XXX
 SG_ CTR : 51|4@0+ (1,0) [0|15] "" XXX
 SG_ NEW_SIGNAL_21 : 23|1@0+ (1,0) [0|15] "" XXX
 SG_ GAS_MAYBE : 22|1@0+ (1,0) [0|1] "" XXX
 SG_ ACCEL_CMD : 46|8@0- (1,0) [0|15] "" XXX
 SG_ CRUISE_ACTIVE_CAR_MOVING : 16|1@0+ (1,0) [0|1] "" XXX
 SG_ PLUS_ONE_CRZ : 17|1@0+ (1,0) [0|255] "" XXX
 SG_ CRZ_STARTED : 18|1@0+ (1,0) [0|1] "" XXX
 SG_ CHKSUM : 63|8@0+ (1,0) [0|15] "" XXX
 SG_ PLUS_ONE_CRZ_2 : 19|1@0+ (1,0) [0|1] "" XXX
 SG_ ACCEL_CMD_LOW_RES : 29|8@0- (1,0) [0|255] "" XXX
 SG_ CRZ_SPEED : 7|16@0+ (0.005,-0.5) [0|328] "kph" XXX

BO_ 542 NEW_MSG_33: 8 XXX
 SG_ CTR : 48|4@1+ (1,0) [0|15] "" XXX
 SG_ CTR2 : 56|4@1+ (1,0) [0|15] "" XXX

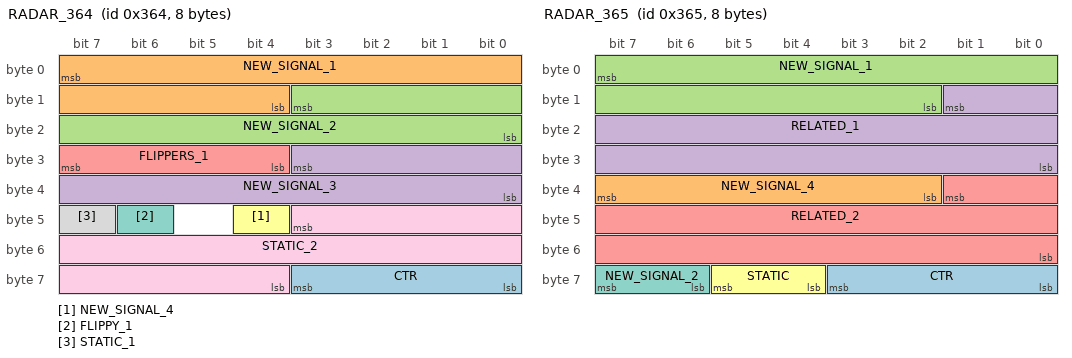
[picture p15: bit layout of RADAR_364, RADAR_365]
BO_ 868 RADAR_364: 8 XXX
 SG_ CTR : 59|4@0+ (1,0) [0|255] "" XXX
 SG_ NEW_SIGNAL_1 : 7|12@0+ (1,0) [0|255] "" XXX
 SG_ NEW_SIGNAL_2 : 11|12@0- (1,0) [0|15] "" XXX
 SG_ NEW_SIGNAL_3 : 27|12@0- (1,0) [0|255] "" XXX
 SG_ FLIPPERS_1 : 31|4@0+ (1,0) [0|15] "" XXX
 SG_ NEW_SIGNAL_4 : 44|1@1+ (1,0) [0|3] "" XXX
 SG_ FLIPPY_1 : 46|1@0+ (1,0) [0|3] "" XXX
 SG_ STATIC_1 : 47|1@0+ (1,0) [0|15] "" XXX
 SG_ STATIC_2 : 43|16@0+ (1,0) [0|7] "" XXX

BO_ 869 RADAR_365: 8 XXX
 SG_ CTR : 59|4@0+ (1,0) [0|255] "" XXX
 SG_ NEW_SIGNAL_4 : 39|6@0+ (1,0) [0|63] "" XXX
 SG_ NEW_SIGNAL_1 : 7|14@0+ (1,0) [0|65535] "" XXX
 SG_ RELATED_1 : 9|18@0+ (1,0) [0|3] "" XXX
 SG_ RELATED_2 : 33|18@0+ (1,0) [0|15] "" XXX
 SG_ STATIC : 61|2@0+ (1,0) [0|3] "" XXX
 SG_ NEW_SIGNAL_2 : 63|2@0+ (1,0) [0|15] "" XXX

BO_ 1114 NEW_MSG_4: 8 XXX

BO_ 535 CURVE_CTRS: 8 XXX
 SG_ CTR_A_1 : 4|3@0+ (1,0) [0|31] "" XXX
 SG_ CTR_A_2 : 7|3@0+ (1,0) [0|255] "" XXX
 SG_ CTR_B_1 : 12|3@0+ (1,0) [0|7] "" XXX
 SG_ CTR_B_2 : 15|3@0+ (1,0) [0|7] "" XXX
 SG_ CTR_C_1 : 20|3@0+ (1,0) [0|7] "" XXX
 SG_ CTR_C_2 : 23|3@0+ (1,0) [0|255] "" XXX
 SG_ CTR_D_2 : 31|3@0+ (1,0) [0|7] "" XXX
 SG_ CTR_D_1 : 28|3@0+ (1,0) [0|7] "" XXX
 SG_ SPEED : 39|16@0+ (0.01,0) [0|7] "kph" XXX
 SG_ CTR : 55|8@0+ (1,0) [0|255] "" XXX
 SG_ CHK_MAYBE : 63|8@0+ (1,0) [0|255] "" XXX
 SG_ NEW_SIGNAL_1 : 0|1@0+ (1,0) [0|1] "" XXX
 SG_ NEW_SIGNAL_2 : 1|1@0+ (1,0) [0|1] "" XXX
 SG_ NEW_SIGNAL_6 : 17|1@0+ (1,0) [0|1] "" XXX
 SG_ NEW_SIGNAL_7 : 24|1@0+ (1,0) [0|1] "" XXX
 SG_ NEW_SIGNAL_8 : 25|1@0+ (1,0) [0|1] "" XXX
 SG_ SEATBELT_MAYBE : 8|1@0+ (1,0) [0|1] "" XXX
 SG_ NO_SEATBELT_MAYBE : 16|1@0+ (1,0) [0|1] "" XXX
 SG_ NEW_SIGNAL_4 : 9|1@0+ (1,0) [0|1] "" XXX

BO_ 540 CRZ_CTRL: 8 XXX
 SG_ NEW_SIGNAL_6 : 10|1@0+ (1,0) [0|1] "" XXX
 SG_ NEW_SIGNAL_9 : 31|1@0+ (1,0) [0|255] "" XXX
 SG_ ACC_GAS_MAYBE2 : 29|1@0+ (1,0) [0|1] "" XXX
 SG_ HANDS_OFF_STEERING : 48|1@0+ (1,0) [0|1] "" XXX
 SG_ HANDS_ON_STEER_WARN : 59|4@0+ (1,0) [0|255] "" XXX
 SG_ CRZ_ACTIVE : 3|1@0+ (1,0) [0|1] "" XXX
 SG_ CRZ_AVAILABLE : 17|1@0+ (1,0) [0|255] "" XXX
 SG_ DISTANCE_SETTING : 20|3@0+ (1,0) [0|7] "" XXX
 SG_ MSG_1_INV : 1|1@0+ (1,0) [0|1] "" XXX
 SG_ MSG_1_COPY : 9|1@0+ (1,0) [0|1] "" XXX
 SG_ ACC_GAS_MAYBE : 23|1@0+ (1,0) [0|31] "" XXX
 SG_ ACC_ACTIVE_2 : 52|1@0+ (1,0) [0|1] "" XXX
 SG_ NEW_SIGNAL_10 : 30|1@0+ (1,0) [0|1] "" XXX
 SG_ MSG_1 : 0|1@0+ (1,0) [0|3] "" XXX
 SG_ 5_SEC_DISABLE_TIMER : 45|3@0+ (1,0) [0|7] "" XXX
 SG_ NEW_SIGNAL_3 : 13|1@0+ (1,0) [0|3] "" XXX
 SG_ MSG_1_INV_COPY : 8|1@0+ (1,0) [0|7] "" XXX
 SG_ RADAR_HAS_LEAD : 23|1@0+ (1,0) [0|1] "" XXX
 SG_ RADAR_LEAD_RELATIVE_DISTANCE : 31|3@0+ (1,0) [0|5] "" XXX

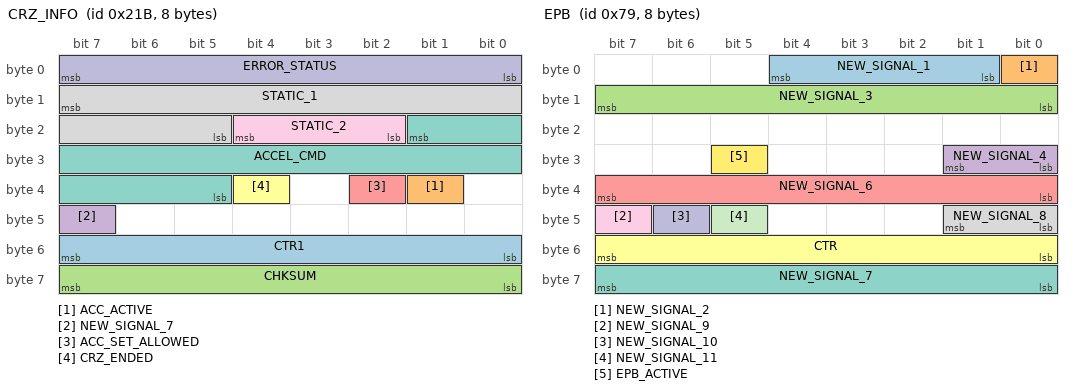
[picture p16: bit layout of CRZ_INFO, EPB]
BO_ 539 CRZ_INFO: 8 XXX
 SG_ CTR1 : 55|8@0+ (1,0) [0|255] "" XXX
 SG_ ACC_ACTIVE : 33|1@0+ (1,0) [0|1] "" XXX
 SG_ CHKSUM : 63|8@0+ (1,0) [0|255] "" XXX
 SG_ NEW_SIGNAL_7 : 47|1@0+ (1,0) [0|255] "" XXX
 SG_ ACC_SET_ALLOWED : 34|1@0+ (1,0) [0|1] "" XXX
 SG_ CRZ_ENDED : 36|1@0+ (1,0) [0|255] "" XXX
 SG_ ACCEL_CMD : 17|13@0+ (1,-4096) [0|1] "" XXX
 SG_ STATIC_1 : 15|11@0+ (1,0) [0|16383] "" XXX
 SG_ STATIC_2 : 18|3@1+ (1,0) [0|3] "" XXX
 SG_ ERROR_STATUS : 7|8@0+ (1,0) [0|255] "" XXX

BO_ 121 EPB: 8 XXX
 SG_ NEW_SIGNAL_1 : 4|4@0+ (1,0) [0|255] "" XXX
 SG_ NEW_SIGNAL_2 : 0|1@0+ (1,0) [0|1] "" XXX
 SG_ NEW_SIGNAL_3 : 15|8@0+ (1,0) [0|255] "" XXX
 SG_ NEW_SIGNAL_4 : 25|2@0+ (1,0) [0|255] "" XXX
 SG_ NEW_SIGNAL_6 : 39|8@0+ (1,0) [0|255] "" XXX
 SG_ CTR : 55|8@0+ (1,0) [0|255] "" XXX
 SG_ NEW_SIGNAL_7 : 63|8@0+ (1,0) [0|255] "" XXX
 SG_ NEW_SIGNAL_8 : 41|2@0+ (1,0) [0|255] "" XXX
 SG_ NEW_SIGNAL_9 : 47|1@0+ (1,0) [0|63] "" XXX
 SG_ NEW_SIGNAL_10 : 46|1@0+ (1,0) [0|1] "" XXX
 SG_ NEW_SIGNAL_11 : 45|1@0+ (1,0) [0|1] "" XXX
 SG_ EPB_ACTIVE : 29|1@0+ (1,0) [0|15] "" XXX

BO_ 1070 2017_1: 8 XXX

BO_ 1183 2017_2: 8 XXX

BO_ 1243 2017_3: 8 XXX
 SG_ NEW_SIGNAL_1 : 7|64@0+ (1,0) [0|18446744073709552000] "" XXX

BO_ 1269 MSG_2017_4: 8 XXX
 SG_ NEW_SIGNAL_1 : 55|16@0+ (1,0) [0|18446744073709552000] "" XXX

BO_ 1178 2017_6: 8 XXX
 SG_ NEW_SIGNAL_1 : 7|64@0+ (1,0) [0|18446744073709552000] "" XXX

BO_ 1179 2017_7: 8 XXX
 SG_ NEW_SIGNAL_1 : 7|64@0+ (1,0) [0|18446744073709552000] "" XXX

BO_ 1435 2017_8: 8 XXX

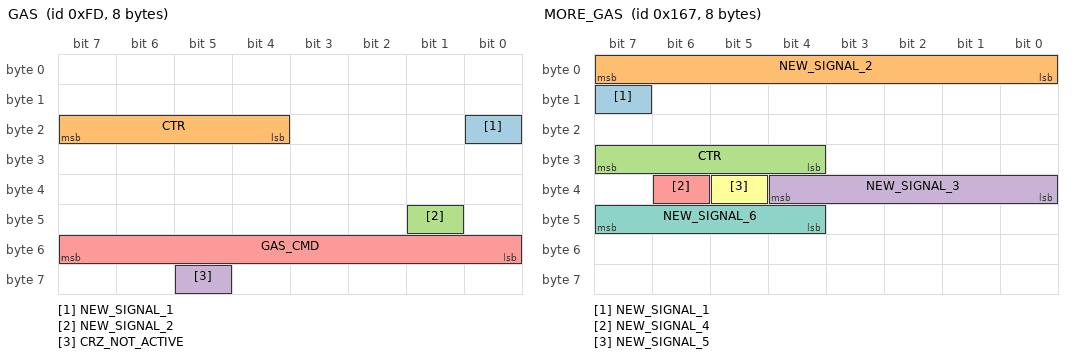
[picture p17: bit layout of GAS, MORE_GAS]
BO_ 253 GAS: 8 XXX
 SG_ NEW_SIGNAL_1 : 16|1@0+ (1,0) [0|65535] "" XXX
 SG_ CTR : 23|4@0+ (1,0) [0|15] "" XXX
 SG_ NEW_SIGNAL_2 : 41|1@0+ (1,0) [0|255] "" XXX
 SG_ CRZ_NOT_ACTIVE : 61|1@0+ (1,0) [0|255] "" XXX
 SG_ GAS_CMD : 55|8@0+ (1,0) [0|255] "" XXX

BO_ 359 MORE_GAS: 8 XXX
 SG_ NEW_SIGNAL_1 : 15|1@0+ (1,0) [0|255] "" XXX
 SG_ NEW_SIGNAL_2 : 7|8@0+ (1,0) [0|255] "" XXX
 SG_ CTR : 31|4@0+ (1,0) [0|255] "" XXX
 SG_ NEW_SIGNAL_3 : 36|5@0+ (1,0) [0|255] "" XXX
 SG_ NEW_SIGNAL_4 : 38|1@1+ (1,0) [0|3] "" XXX
 SG_ NEW_SIGNAL_5 : 37|1@0+ (1,0) [0|1] "" XXX
 SG_ NEW_SIGNAL_6 : 47|4@0+ (1,0) [0|255] "" XXX

BO_ 512 NEW_MSG_30: 8 XXX
 SG_ NEW_SIGNAL_1 : 6|7@0+ (1,0) [0|255] "" XXX
 SG_ NEW_SIGNAL_2 : 7|1@0+ (1,0) [0|1] "" XXX
 SG_ NEW_SIGNAL_3 : 15|8@0+ (1,0) [0|255] "" XXX
 SG_ NEW_SIGNAL_4 : 23|1@0+ (1,0) [0|255] "" XXX
 SG_ NEW_SIGNAL_5 : 22|7@0+ (1,0) [0|127] "" XXX
 SG_ NEW_SIGNAL_6 : 31|8@0+ (1,0) [0|255] "" XXX
 SG_ NEW_SIGNAL_7 : 39|1@0+ (1,0) [0|1] "" XXX
 SG_ NEW_SIGNAL_8 : 38|7@0+ (1,0) [0|127] "" XXX
 SG_ NEW_SIGNAL_9 : 40|4@1+ (1,0) [0|15] "" XXX
 SG_ NEW_SIGNAL_10 : 47|4@0+ (1,0) [0|15] "" XXX
 SG_ CTR : 51|3@0+ (1,0) [0|255] "" XXX
 SG_ NEW_SIGNAL_11 : 63|8@0+ (1,0) [0|255] "" XXX

BO_ 515 MSG_01: 8 XXX
 SG_ CTR : 39|4@0+ (1,0) [0|65535] "" XXX
 SG_ CHKSUM : 47|8@0+ (1,0) [0|255] "" XXX
 SG_ START1 : 6|1@0+ (1,0) [0|1] "" XXX
 SG_ START2 : 28|5@0+ (1,0) [0|255] "" XXX

BO_ 529 NEW_MSG_36: 8 XXX
 SG_ NEW_SIGNAL_1 : 22|5@0+ (1,0) [0|65535] "" XXX
 SG_ NEW_SIGNAL_2 : 31|8@0+ (1,0) [0|15] "" XXX
 SG_ NEW_SIGNAL_3 : 32|4@1+ (1,0) [0|3] "" XXX
 SG_ CTR : 39|4@0+ (1,0) [0|255] "" XXX
 SG_ CTR_2 : 47|4@0+ (1,0) [0|255] "" XXX
 SG_ NEW_SIGNAL_4 : 40|4@1+ (1,0) [0|3] "" XXX
 SG_ NEW_SIGNAL_5 : 53|1@0+ (1,0) [0|255] "" XXX

BO_ 1242 NEW_MSG_37: 8 XXX

BO_ 1266 MSG_09: 8 XXX
 SG_ NEW_SIGNAL_1 : 20|1@0+ (1,0) [0|255] "" XXX
 SG_ NEW_SIGNAL_2 : 19|4@0+ (1,0) [0|1] "" XXX
 SG_ NEW_SIGNAL_3 : 31|1@0+ (1,0) [0|255] "" XXX

BO_ 976 MSG_15: 8 XXX
 SG_ NEW_SIGNAL_1 : 55|1@0+ (1,0) [0|255] "" XXX
 SG_ NEW_SIGNAL_2 : 61|6@0+ (1,0) [0|1] "" XXX

BO_ 155 MSG_14: 8 XXX

BO_ 1267 MSG_10: 8 XXX
 SG_ NEW_SIGNAL_1 : 40|1@0+ (1,0) [0|16777215] "" XXX
 SG_ NEW_SIGNAL_2 : 42|1@0+ (1,0) [0|1] "" XXX

BO_ 305 NEW_MSG_6: 8 XXX
 SG_ NEW_SIGNAL_1 : 8|1@0+ (1,0) [0|255] "" XXX
 SG_ NEW_SIGNAL_2 : 9|1@0+ (1,0) [0|1] "" XXX
 SG_ NEW_SIGNAL_3 : 10|1@0+ (1,0) [0|1] "" XXX

BO_ 1238 TEMPERATURE: 8 XXX
 SG_ TEMPERATURE_MAYBE : 47|8@0+ (1,0) [0|4294967295] "" XXX

BO_ 1087 NEW_MSG_1: 8 XXX
 SG_ NEW_SIGNAL_1 : 7|8@0+ (1,0) [0|255] "" XXX

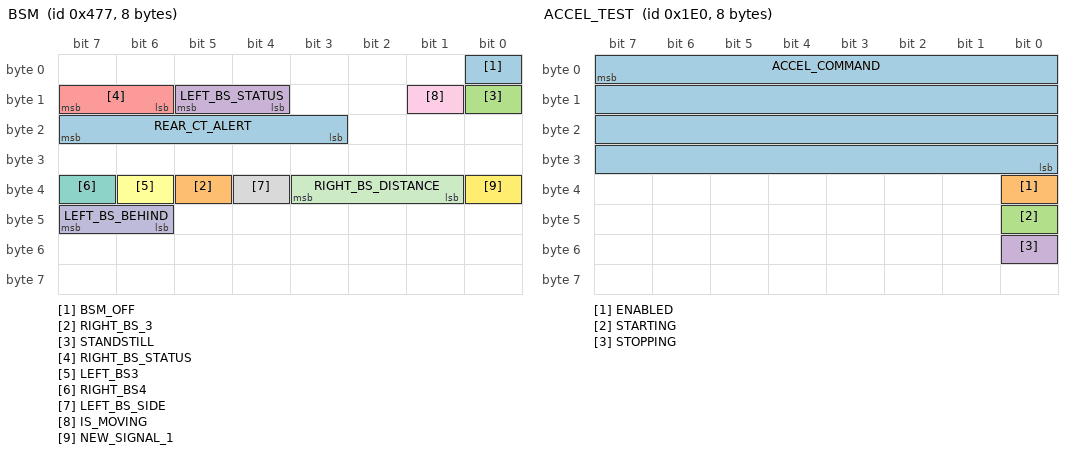
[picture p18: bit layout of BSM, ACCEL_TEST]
BO_ 1143 BSM: 8 XXX
 SG_ BSM_OFF : 0|1@0+ (1,0) [0|1] "" XXX
 SG_ RIGHT_BS_3 : 37|1@0+ (1,0) [0|1] "" XXX
 SG_ STANDSTILL : 8|1@0+ (1,0) [0|1] "" XXX
 SG_ LEFT_BS_STATUS : 13|2@0+ (1,0) [0|3] "" XXX
 SG_ RIGHT_BS_STATUS : 15|2@0+ (1,0) [0|3] "" XXX
 SG_ LEFT_BS3 : 38|1@0+ (1,0) [0|1] "" XXX
 SG_ RIGHT_BS4 : 39|1@0+ (1,0) [0|1] "" XXX
 SG_ LEFT_BS_SIDE : 36|1@0+ (1,0) [0|1] "" XXX
 SG_ IS_MOVING : 9|1@0+ (1,0) [0|1] "" XXX
 SG_ LEFT_BS_BEHIND : 46|2@1+ (1,0) [0|16777215] "" XXX
 SG_ RIGHT_BS_DISTANCE : 35|3@0+ (1,0) [0|1] "" XXX
 SG_ NEW_SIGNAL_1 : 32|1@0+ (1,0) [0|1] "" XXX
 SG_ REAR_CT_ALERT : 23|5@0+ (1,0) [0|63] "" XXX

BO_ 480 ACCEL_TEST: 8 XXX
 SG_ ACCEL_COMMAND : 7|32@0- (1,0) [-2147483647|2147483647] "" XXX
 SG_ ENABLED : 32|1@0+ (1,0) [0|1] "" XXX
 SG_ STARTING : 40|1@0+ (1,0) [0|1] "" XXX
 SG_ STOPPING : 48|1@0+ (1,0) [0|1] "" XXX

BO_ 1361 KEY_POSITION: 8 XXX

BO_ 1283 KEY_POSITION2: 8 XXX

BO_ 628 MSG_06: 8 XXX

BO_ 1154 MSG_08: 8 XXX

BO_ 1139 MSG_13: 8 XXX

BO_ 1270 MSG_16: 8 XXX

BO_ 1272 MSG_17: 8 XXX

BO_ 1425 MSG_19: 8 XXX

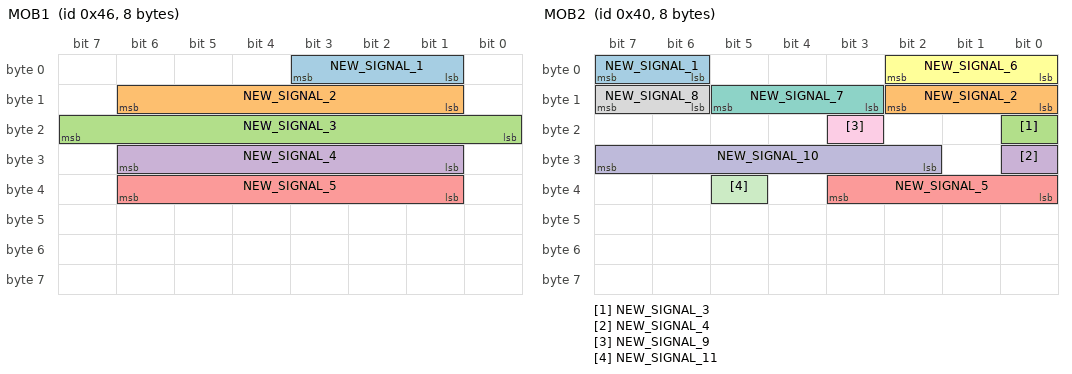
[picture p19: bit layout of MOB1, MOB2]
BO_ 70 MOB1: 8 XXX
 SG_ NEW_SIGNAL_1 : 1|3@1+ (1,0) [0|15] "" XXX
 SG_ NEW_SIGNAL_2 : 14|6@0+ (1,0) [0|127] "" XXX
 SG_ NEW_SIGNAL_3 : 23|8@0+ (1,0) [0|255] "" XXX
 SG_ NEW_SIGNAL_4 : 30|6@0+ (1,0) [0|255] "" XXX
 SG_ NEW_SIGNAL_5 : 38|6@0+ (1,0) [0|7] "" XXX

BO_ 64 MOB2: 8 XXX
 SG_ NEW_SIGNAL_1 : 7|2@0+ (1,0) [0|255] "" XXX
 SG_ NEW_SIGNAL_2 : 10|3@0+ (1,0) [0|255] "" XXX
 SG_ NEW_SIGNAL_3 : 16|1@0+ (1,0) [0|255] "" XXX
 SG_ NEW_SIGNAL_4 : 24|1@0+ (1,0) [0|255] "" XXX
 SG_ NEW_SIGNAL_5 : 35|4@0+ (1,0) [0|255] "" XXX
 SG_ NEW_SIGNAL_6 : 0|3@1+ (1,0) [0|7] "" XXX
 SG_ NEW_SIGNAL_7 : 13|3@0+ (1,0) [0|3] "" XXX
 SG_ NEW_SIGNAL_8 : 15|2@0+ (1,0) [0|3] "" XXX
 SG_ NEW_SIGNAL_9 : 19|1@0+ (1,0) [0|1] "" XXX
 SG_ NEW_SIGNAL_10 : 31|6@0+ (1,0) [0|3] "" XXX
 SG_ NEW_SIGNAL_11 : 37|1@0+ (1,0) [0|1] "" XXX

BO_ 1171 MOB3: 8 XXX

BO_ 1248 MOB4: 8 XXX

BO_ 1177 RADAR_499_STATIC: 8 XXX

BU_: RRSRR_FO LRSRR_FO CIPM_FO _DOFIMU2_FO _DOFIMU1_FO DMS_FO AMM_FO EOCM2B_IMX6_FO EOCM2B_K2_FO EOCM2B_K1_FO EOCM2A_IMX6_FO EOCM2A_K2_FO EOCM2A_K1_FO NVS_FO Dummy_FO TestTool_FO LRR_FO RFSRR_FO LFSRR_FO RSRR_FO VIS_FO EOCM_F_FO VIS2_FO
VAL_TABLE_ vt_BooleanValues 1 "true" 0 "false" ;
VAL_TABLE_ FrntVsnInPthVehBrkNwSt 10 "Active" 5 "Inactive" ;
VAL_TABLE_ FrntVsnClostPedBrkNwSt 10 "Active" 5 "Inactive" ;
VAL_TABLE_ DrvrMonSysEngSt 7 "Unused and Reserved 1" 6 "Recovering" 5 "Tracking" 4 "Searching" 3 "Video test port only" 2 "Idle" 1 "Invalid state" 0 "Does not exist or DME" ;
VAL_TABLE_ DrvrMonEngUnrecvrFltCod 7 "Unused and Reserved 3" 6 "Unused and Reserved 2" 5 "Unused and Reserved 1" 4 "Vehicle power supply Errors" 3 "Problem with LED illuminators" 2 "Vehicle input signals Errors" 1 "Problem with imager" 0 "Ok" ;
VAL_TABLE_ DrvrMonEngRecvrFltCod 3 "Engine is unable to find a face" 2 "Input Images too dark" 1 "Input images too bright" 0 "Ok" ;
VAL_TABLE_ DrvrMntrSysVTP 1 "Video test port active" 0 "Video test port inactive" ;
VAL_TABLE_ DrvrAttnStatCnfdc 3 "High" 2 "Medium" 1 "Low" 0 "Lowest" ;
VAL_TABLE_ DrvrAttnStat 7 "Invalid" 6 "Driver is exhibiting sleep" 5 "Driver is exhibiting microsleep" 4 "Attention is Center Console" 3 "Attention is Drivers Lap" 2 "Attention is Off Road" 1 "Attention is On Road" 0 "Unknown" ;
VAL_TABLE_ PPSMd 7 "GNSS and RTX and DR and MM" 6 "DR ONLY" 5 "GNSS and RTX and DR" 4 "GNSS and SBAS and DR" 3 "GNSS and DR" 2 "GNSS and  RTX" 1 "GNSS and SBAS" 0 "GNSS Standalone" ;
VAL_TABLE_ AdvDrvAstMpPrfShrtAcur 3 "Accuracy Is Unknown" 2 "Lowest Accuracy" 1 "Medium Accuracy" 0 "Highest Accuracy" ;
VAL_TABLE_ AdvDrAstMpStbRtOfWay 3 "Not Applicable" 2 "Unknown" 1 "Sub Path Has Right Of Way Over Path" 0 "Path Has Right Of Way Over Sub Path" ;
VAL_TABLE_ AdvDrAstMpStbPrtCalRut 3 "Not Applicable" 2 "Unknown" 1 "Path From This Point On Is Part Of Calculated Route" 0 "Path From This Point On Is Not Part Of Calculated Route" ;
VAL_TABLE_ AdvDrAstMpStbMsgTyp 7 "Unused and Reserved 2" 6 "Metadata" 5 "Profile Long" 4 "Profile Short" 3 "Stub" 2 "Segment" 1 "Position" 0 "Unused and Reserved 1" ;
VAL_TABLE_ AdvDrAstMpStbFmOfWay 15 "Not Applicable" 14 "Pedestrian Zone" 13 "Entrance To Or Exit To Service" 12 "Entrance To Or Exit Of A Car Park" 11 "Service Road Or Frontage Road" 10 "Slip Road per Ramp" 9 "Slip Road per Ramp On A Freeway Or Controlled Access Road" 8 "Parallel Road" 7 "Unused and Reserved 2" 6 "Unused and Reserved 1" 5 "Traffic Square per Special Traffic Figure" 4 "Roundabout Circle" 3 "Single Carriageway" 2 "Multiple Carriageway Or Multiply Digitized Road" 1 "Freeway Or Controlled Access Road That Is Not A Slip Road Or Ramp" 0 "Unknown" ;
VAL_TABLE_ AdvDrAstMpStbCmplxInsct 3 "Not Applicable" 2 "Unknown" 1 "Stub Is Part Of Complex Intersection" 0 "Stub Is Not Part Of Complex Intersection" ;
VAL_TABLE_ AdvDrAstMpSegTunl 3 "Not Applicable" 2 "Unknown" 1 "Segment Is Part Of Tunnel" 0 "Segment Is Not A Part Of Tunnel" ;
VAL_TABLE_ AdvDrAstMpSegPrtCalRut 3 "Not Applicable" 2 "Unknown" 1 "Segment Is Part Of Calculated Route" 0 "Segment Is Not Part Of Calculated Route" ;
VAL_TABLE_ AdvDrAstMpSegMsgTyp 7 "Unused and Reserved 2" 6 "Metadata" 5 "Profile Long" 4 "Profile Short" 3 "Stub" 2 "Segment" 1 "Position" 0 "Unused and Reserved 1" ;
VAL_TABLE_ AdvDrAstMpSegFrmOfWay 15 "Not Applicable" 14 "Pedestrian Zone" 13 "Entrance To Or Exit To Service" 12 "Entrance To Or Exit Of A Car Park" 11 "Service Road Or Frontage Road" 10 "Slip Road per Ramp" 9 "Slip Road per Ramp On A Freeway Or Controlled Access Road" 8 "Parallel Road" 7 "Unused and Reserved 2" 6 "Unused and Reserved 1" 5 "Traffic Square per Special Traffic Figure" 4 "Roundabout Circle" 3 "Single Carriageway" 2 "Multiple Carriageway Or Multiply Digitized Road" 1 "Freeway Or Controlled Access Road That Is Not A Slip Road or Ramp" 0 "Unknown" ;
VAL_TABLE_ AdvDrAstMpSegEffSdLmtTp 7 "Not Applicable" 6 "Explicit Snow" 5 "Explicit Rain" 4 "Explicit Time Of Day" 3 "Explicit By Day" 2 "Explicit By Night" 1 "Explicit On Traffic Sign" 0 "Implicit" ;
VAL_TABLE_ AdvDrAstMpSegDivdRd 3 "Not Applicable" 2 "Unknown" 1 "Segment Is Part Of Divided Road" 0 "Segment Is Not Part Of Divided Road" ;
VAL_TABLE_ AdvDrAstMpSegCmplxInsct 3 "Not Applicable" 2 "Unknown" 1 "Segment Is Part Of Complex Intersection" 0 "Segment Is Not Part Of Complex Intersection" ;
VAL_TABLE_ AdvDrAstMpSegBrdg 3 "Not Applicable" 2 "Unknown" 1 "Segment Is Part Of Bridge" 0 "Segment Not Part Of Bridge" ;
VAL_TABLE_ AdvDrAstMpSegBldUpAra 3 "Not Applicable" 2 "Unknown" 1 "Segment Is Part Of Built Up Area" 0 "Segment Is Not Part Of Built Up Area" ;
VAL_TABLE_ AdvDrAstMpMtdtSpdUnt 1 "Miles Per Hour" 0 "Kilometers Per Hour" ;
VAL_TABLE_ AdvDrAstMpMtdtDrvSd 1 "Driving Side Right" 0 "Driving Side Left" ;
VAL_TABLE_ WSMR_WiFiAssnReq 3 "Unexpected Undefined Connection Behavior" 2 "Wi Fi association failed with available credentials" 1 "Failed to receive Wi Fi credentials after 255 attempts" 0 "SSID and Passphrase Request" ;
VAL_TABLE_ StrgColCommsFlt 2 "Disabled Communications DTC" 1 "No Communications Fault" 0 "Communications Fault" ;
VAL_TABLE_ CPMAPINFO4 1 "Hardware Or Software Error" 0 "No Hardware Or Software Error" ;
VAL_TABLE_ AdvDrvAstMpPrfShrt2Acur 3 "Accuracy Is Unknown" 2 "Lowest Accuracy" 1 "Medium Accuracy" 0 "Highest Accuracy" ;
VAL_TABLE_ InterLghtStat 1 "Interior Lights On" 0 "Interior Light Off" ;
VAL_TABLE_ VehLnStatConf 2 "High Confidence" 1 "Low Confidence" 0 "No Confidence" 3 "Very High Confidence" ;
VAL_TABLE_ VehLnStat 3 "Lane Change To Right" 2 "Lane Change To Left" 1 "Staying in Lane" 0 "Unknown" ;
VAL_TABLE_ HrznPrvdRstRq 1 "Reset Not Required" 0 "Reset Required" ;
VAL_TABLE_ ExptNxtTrnstnDirConf 3 "Very High Confidence" 2 "High Confidence" 1 "Low Confidence" 0 "No Confidence" ;
VAL_TABLE_ ExptNxtTrnstnDir 7 "Reserved4" 6 "Reserved3" 5 "Reserved2" 4 "Reserved1" 3 "Traversing Middle Transition" 2 "Traversing Next Transition Right" 1 "Traversing Next Transition Left" 0 "Unknown" ;
VAL_TABLE_ ADASISMsgTypRetrans 7 "GM System Specific" 6 "Meta Data" 5 "Profile Long" 4 "Profile Short" 3 "Stub" 2 "Segment" 1 "Position" 0 "Checksum" ;
VAL_TABLE_ NVSysStat 7 "Needs Headlights" 6 "Temporarily Unavailable" 5 "Not Dark" 4 "Needs Service" 3 "Active" 2 "Inactive" 1 "Initializing" 0 "Unknown" ;
VAL_TABLE_ NVSysPedWrnIndReq 3 "Unused & Reserved" 2 "Pedestrian Alert" 1 "Pedestrian Detected" 0 "None" ;
VAL_TABLE_ NVSysPedDetCstReq 2 "On" 1 "Off" 0 "No Value" ;
VAL_TABLE_ NVSysPedDetCsCrStVal 2 "On" 1 "Off" 0 "No Value" ;
VAL_TABLE_ FwVsnCinCoutPotT9Rev 2 "Right" 1 "Left" 0 "None" ;
VAL_TABLE_ FwVsnCinCoutPotT8Rev 2 "Right" 1 "Left" 0 "None" ;
VAL_TABLE_ FwVsnCinCoutPotT7Rev 2 "Right" 1 "Left" 0 "None" ;
VAL_TABLE_ FwVsnCinCoutPotT6Rev 2 "Right" 1 "Left" 0 "None" ;
VAL_TABLE_ FwVsnCinCoutPotT5Rev 2 "Right" 1 "Left" 0 "None" ;
VAL_TABLE_ FwVsnCinCoutPotT4Rev 2 "Right" 1 "Left" 0 "None" ;
VAL_TABLE_ FwVsnCinCoutPotT3Rev 2 "Right" 1 "Left" 0 "None" ;
VAL_TABLE_ FwVsnCinCoutPotT2Rev 2 "Right" 1 "Left" 0 "None" ;
VAL_TABLE_ FwVsnCinCoutPotT1Rev 2 "Right" 1 "Left" 0 "None" ;
VAL_TABLE_ FwVsnCinCoutPotT12Rev 2 "Right" 1 "Left" 0 "None" ;
VAL_TABLE_ FwVsnCinCoutPotT11Rev 2 "Right" 1 "Left" 0 "None" ;
VAL_TABLE_ FwVsnCinCoutPotT10Rev 2 "Right" 1 "Left" 0 "None" ;
VAL_TABLE_ GFHBObjDirTrk8 1 "Ahead Traffic" 0 "Incoming Traffic" ;
VAL_TABLE_ GFHBObjDirTrk7 1 "Ahead Traffic" 0 "Incoming Traffic" ;
VAL_TABLE_ GFHBObjDirTrk6 1 "Ahead Traffic" 0 "Incoming Traffic" ;
VAL_TABLE_ GFHBObjDirTrk5 1 "Ahead Traffic" 0 "Incoming Traffic" ;
VAL_TABLE_ GFHBObjDirTrk4 1 "Ahead Traffic" 0 "Incoming Traffic" ;
VAL_TABLE_ GFHBObjDirTrk3 1 "Ahead Traffic" 0 "Incoming Traffic" ;
VAL_TABLE_ GFHBObjDirTrk2 1 "Ahead Traffic" 0 "Incoming Traffic" ;
VAL_TABLE_ GFHBObjDirTrk1 1 "Ahead Traffic" 0 "Incoming Traffic" ;
VAL_TABLE_ GFHBFwVsnRelLaneTrk8 3 "Left Lane" 2 "Right Lane" 1 "Host Lane" 0 "Unknown" ;
VAL_TABLE_ GFHBFwVsnRelLaneTrk7 3 "Left Lane" 2 "Right Lane" 1 "Host Lane" 0 "Unknown" ;
VAL_TABLE_ GFHBFwVsnRelLaneTrk6 3 "Left Lane" 2 "Right Lane" 1 "Host Lane" 0 "Unknown" ;
VAL_TABLE_ GFHBFwVsnRelLaneTrk5 3 "Left Lane" 2 "Right Lane" 1 "Host Lane" 0 "Unknown" ;
VAL_TABLE_ GFHBFwVsnRelLaneTrk4 3 "Left Lane" 2 "Right Lane" 1 "Host Lane" 0 "Unknown" ;
VAL_TABLE_ GFHBFwVsnRelLaneTrk3 3 "Left Lane" 2 "Right Lane" 1 "Host Lane" 0 "Unknown" ;
VAL_TABLE_ GFHBFwVsnRelLaneTrk2 3 "Left Lane" 2 "Right Lane" 1 "Host Lane" 0 "Unknown" ;
VAL_TABLE_ GFHBFwVsnRelLaneTrk1 3 "Left Lane" 2 "Right Lane" 1 "Host Lane" 0 "Unknown" ;
VAL_TABLE_ GFHBFwVsnMesStatTrk8 3 "Measured this cycle" 2 "Latent track not detected this cycle" 1 "New Object" 0 "No Object" ;
VAL_TABLE_ GFHBFwVsnMesStatTrk7 3 "Measured this cycle" 2 "Latent track not detected this cycle" 1 "New Object" 0 "No Object" ;
VAL_TABLE_ GFHBFwVsnMesStatTrk6 3 "Measured this cycle" 2 "Latent track not detected this cycle" 1 "New Object" 0 "No Object" ;
VAL_TABLE_ GFHBFwVsnMesStatTrk5 3 "Measured this cycle" 2 "Latent track not detected this cycle" 1 "New Object" 0 "No Object" ;
VAL_TABLE_ GFHBFwVsnMesStatTrk4 3 "Measured this cycle" 2 "Latent track not detected this cycle" 1 "New Object" 0 "No Object" ;
VAL_TABLE_ GFHBFwVsnMesStatTrk3 3 "Measured this cycle" 2 "Latent track not detected this cycle" 1 "New Object" 0 "No Object" ;
VAL_TABLE_ GFHBFwVsnMesStatTrk2 3 "Measured this cycle" 2 "Latent track not detected this cycle" 1 "New Object" 0 "No Object" ;
VAL_TABLE_ GFHBFwVsnMesStatTrk1 3 "Measured this cycle" 2 "Latent track not detected this cycle" 1 "New Object" 0 "No Object" ;
VAL_TABLE_ GFHBFwVsnCnfdncTrk8 3 "Confident" 2 "Speculative" 1 "Highly Speculative" 0 "Invalid" ;
VAL_TABLE_ GFHBFwVsnCnfdncTrk7 3 "Confident" 2 "Speculative" 1 "Highly Speculative" 0 "Invalid" ;
VAL_TABLE_ GFHBFwVsnCnfdncTrk6 3 "Confident" 2 "Speculative" 1 "Highly Speculative" 0 "Invalid" ;
VAL_TABLE_ GFHBFwVsnCnfdncTrk5 3 "Confident" 2 "Speculative" 1 "Highly Speculative" 0 "Invalid" ;
VAL_TABLE_ GFHBFwVsnCnfdncTrk4 3 "Confident" 2 "Speculative" 1 "Highly Speculative" 0 "Invalid" ;
VAL_TABLE_ GFHBFwVsnCnfdncTrk3 3 "Confident" 2 "Speculative" 1 "Highly Speculative" 0 "Invalid" ;
VAL_TABLE_ GFHBFwVsnCnfdncTrk2 3 "Confident" 2 "Speculative" 1 "Highly Speculative" 0 "Invalid" ;
VAL_TABLE_ GFHBFwVsnCnfdncTrk1 0 "Invalid" 3 "Confident" 2 "Speculative" 1 "Highly Speculative" ;
VAL_TABLE_ GFHBFVsnObjTypTrkRev8 12 "Cluster Object" 11 "Child Close to Danger Zone" 10 "Pedestrian Moving Out of Danger Zone" 9 "Pedestrian Moving Into Danger Zone" 8 "Pedestrian Standing Outside Danger Zone" 7 "No Object Present" 6 "Fixed Roadside Object" 5 "Fixed Overhead Object" 4 "Pedestrian" 3 "Motorcycle/ Bicycle" 2 "Large Vehicle (Semi)" 1 "4 Wheel Vehicle (Car)" 0 "Unknown" ;
VAL_TABLE_ GFHBFVsnObjTypTrkRev7 12 "Cluster Object" 11 "Child Close to Danger Zone" 10 "Pedestrian Moving Out of Danger Zone" 9 "Pedestrian Moving Into Danger Zone" 8 "Pedestrian Standing Outside Danger Zone" 7 "No Object Present" 6 "Fixed Roadside Object" 5 "Fixed Overhead Object" 4 "Pedestrian" 3 "Motorcycle/ Bicycle" 2 "Large Vehicle (Semi)" 1 "4 Wheel Vehicle (Car)" 0 "Unknown" ;
VAL_TABLE_ GFHBFVsnObjTypTrkRev6 12 "Cluster Object" 11 "Child Close to Danger Zone" 10 "Pedestrian Moving Out of Danger Zone" 9 "Pedestrian Moving Into Danger Zone" 8 "Pedestrian Standing Outside Danger Zone" 7 "No Object Present" 6 "Fixed Roadside Object" 5 "Fixed Overhead Object" 4 "Pedestrian" 3 "Motorcycle/ Bicycle" 2 "Large Vehicle (Semi)" 1 "4 Wheel Vehicle (Car)" 0 "Unknown" ;
VAL_TABLE_ GFHBFVsnObjTypTrkRev5 12 "Cluster Object" 11 "Child Close to Danger Zone" 10 "Pedestrian Moving Out of Danger Zone" 9 "Pedestrian Moving Into Danger Zone" 8 "Pedestrian Standing Outside Danger Zone" 7 "No Object Present" 6 "Fixed Roadside Object" 5 "Fixed Overhead Object" 4 "Pedestrian" 3 "Motorcycle/ Bicycle" 2 "Large Vehicle (Semi)" 1 "4 Wheel Vehicle (Car)" 0 "Unknown" ;
VAL_TABLE_ GFHBFVsnObjTypTrkRev4 12 "Cluster Object" 11 "Child Close to Danger Zone" 10 "Pedestrian Moving Out of Danger Zone" 9 "Pedestrian Moving Into Danger Zone" 8 "Pedestrian Standing Outside Danger Zone" 7 "No Object Present" 6 "Fixed Roadside Object" 5 "Fixed Overhead Object" 4 "Pedestrian" 3 "Motorcycle/ Bicycle" 2 "Large Vehicle (Semi)" 1 "4 Wheel Vehicle (Car)" 0 "Unknown" ;
VAL_TABLE_ GFHBFVsnObjTypTrkRev3 12 "Cluster Object" 11 "Child Close to Danger Zone" 10 "Pedestrian Moving Out of Danger Zone" 9 "Pedestrian Moving Into Danger Zone" 8 "Pedestrian Standing Outside Danger Zone" 7 "No Object Present" 6 "Fixed Roadside Object" 5 "Fixed Overhead Object" 4 "Pedestrian" 3 "Motorcycle/ Bicycle" 2 "Large Vehicle (Semi)" 1 "4 Wheel Vehicle (Car)" 0 "Unknown" ;
VAL_TABLE_ GFHBFVsnObjTypTrkRev2 12 "Cluster Object" 11 "Child Close to Danger Zone" 10 "Pedestrian Moving Out of Danger Zone" 9 "Pedestrian Moving Into Danger Zone" 8 "Pedestrian Standing Outside Danger Zone" 7 "No Object Present" 6 "Fixed Roadside Object" 5 "Fixed Overhead Object" 4 "Pedestrian" 3 "Motorcycle/ Bicycle" 2 "Large Vehicle (Semi)" 1 "4 Wheel Vehicle (Car)" 0 "Unknown" ;
VAL_TABLE_ GFHBFVsnObjTypTrkRev1 12 "Cluster Object" 11 "Child Close to Danger Zone" 10 "Pedestrian Moving Out of Danger Zone" 9 "Pedestrian Moving Into Danger Zone" 8 "Pedestrian Standing Outside Danger Zone" 7 "No Object Present" 6 "Fixed Roadside Object" 5 "Fixed Overhead Object" 4 "Pedestrian" 3 "Motorcycle/ Bicycle" 2 "Large Vehicle (Semi)" 1 "4 Wheel Vehicle (Car" 0 "Unknown" ;
VAL_TABLE_ CRL_Cnfdnc 7 "Reserved4" 6 "Reserved3" 5 "Reserved2" 4 "Reserved1" 3 "Best" 2 "Marking Present" 1 "Weak Marking" 0 "No Lane" ;
VAL_TABLE_ CLL_Cnfdnc 7 "Reserved4" 6 "Reserved3" 5 "Reserved2" 4 "Reserved1" 3 "Best" 2 "Marking Present" 1 "Weak Marking" 0 "No Lane" ;
VAL_TABLE_ VBBrkCtrlSt 4 "Release Control" 3 "Hold Vehicle" 2 "Apply Brake" 1 "Decrease Torque" 0 "No Action" ;
VAL_TABLE_ ObstacleType 6 "NO_OBJECT" 5 "OBJ_GUARDRAIL" 4 "OBJ_TUNNEL " 3 "OBJ_TRAFFIC_SIGN" 2 "OBJ_VEHICLE" 1 "OBJ_BRIDGE " 0 "OBJ_UNKNOWN" ;
VAL_TABLE_ VpathMode 2 "Mid Hi Speed" 1 "Low Speed" 0 "Disabled" ;
VAL_TABLE_ LaneChngStatus 2 "Lane Change Right" 1 "Lane Change Left" 0 "Idle" ;
VAL_TABLE_ TravelDirection 3 "Other (excessive side slip)" 2 "reverse / stopped in rvrs gear" 1 "Forward / stopped in frwd gear" 0 "Unknown" ;
VAL_TABLE_ TrueOrFalse 1 "true" 0 "false" ;
VAL_TABLE_ ModeCommand 5 "Sensing with Reduced Power" 4 "Undefined" 3 "Radio Silent" 2 "Sensing" 1 "Not Sensing" 0 "Undefined" ;
VAL_TABLE_ LaneSnsLLnPosValid 1 "Invalid" 0 "Valid" ;
VAL_TABLE_ LnSnsRLnPosValid 1 "Invalid" 0 "Valid" ;
VAL_TABLE_ Elevation 3 "Low " 2 "mid (reserved)" 1 "high " 0 "Unknown" ;
VAL_TABLE_ ModeCommandFdbk 5 "Sensing with reduced power" 4 "Undefined" 3 "Radio Silent" 2 "Sensing" 1 "Not Sensing" 0 "Undefined" ;
VAL_TABLE_ relativeLane 3 "Left Lane" 2 "Right Lane" 1 "Host Lane" 0 "Unknown" ;
VAL_TABLE_ RoadTypeInfo 5 "Constiction Zone Exit" 4 "Construction Zone Entry" 3 "Highway" 2 "Secondary Road" 1 "City" 0 "Unknown" ;
VAL_TABLE_ ObjectLossInfo 2 "elevation conditions" 1 "tight curve" 0 "not lost" ;
VAL_TABLE_ MeasurementStatus 3 "Measured this cycle" 2 "Latent track not detctd this cyc" 1 "New Object" 0 "No Object" ;
VAL_TABLE_ ObjectType 7 "no object present" 6 "fixed roadside object" 5 "fixed overhead object" 4 "pedestrian" 3 "motocycle  / bicycle" 2 "Large vehicle (semi)" 1 "4 Wheel Vehicle (car, small trk)" 0 "Unknown" ;
VAL_TABLE_ Confidence 3 "confident" 2 "speculative" 1 "highly speculative" 0 "invalid" ;
VAL_TABLE_ DynamicProp 4 "Moving in opposite direction" 3 "Moving in same direction as host" 2 "Has moved but currently stopped" 1 "Has never moved" 0 "Unknown" ;
VAL_TABLE_ DrvWndPosSt 6 "Fully Opened" 5 "Open More Than C" 4 "Position C" 3 "Position B" 2 "Position A" 1 "Open Less Than A" 0 "Fully Closed" ;
VAL_TABLE_ VehMovSta 4 "Invalid" 3 "Reverse" 2 "Forward" 1 "Neutral" 0 "Parked" ;
VAL_TABLE_ OtsdAmbtLtLvlStat 2 "Day" 1 "Night" 0 "Unknown" ;
VAL_TABLE_ RtTrnLmpAtv 2 "On with telltale" 1 "On without telltale" 0 "Off" ;
VAL_TABLE_ LftTrnLmpAtv 2 "On with telltale" 1 "On without telltale" 0 "Off" ;
VAL_TABLE_ HdlmpBmSelectStat 2 "High Beams" 1 "Low Beams" 0 "Unknown" ;
VAL_TABLE_ DTCI_DTCFaultType 3 "Type C" 2 "Type B" 1 "Type A" 0 "Not Supported" ;
VAL_TABLE_ TrnsShftLvrPos 13 "Forward Range J" 12 "Forward Range I" 15 "Lever Position Unknown" 11 "Forward Range H" 10 "Forward Range G" 9 "Forward Range F" 8 "Forward Range E" 7 "Forward Range D" 6 "Forward Range C" 5 "Forward Range B" 4 "Forward Range A" 3 "Neutral Range" 2 "Reverse Range" 1 "Park Range" 0 "Between Ranges" ;
VAL_TABLE_ SysPwrMd 3 "Crank Request" 2 "Run" 1 "Accessory" 0 "Off" ;
VAL_TABLE_ ValidityStates 1 "Invalid" 0 "Valid" ;

CM_ SG_ 970 Lkas_Action "only vals 4, 5, 8, 9 seem to work. 4 and 5 are a bit smoother" ;

VAL_ 780 CRUISE_SPEED 255 "no_speed" 252 "stopped";
VAL_ 780 HUD_LEAD 3 "acc_off" 2 "solid_car" 1 "dashed_car" 0 "no_car";
VAL_ 884 DASHBOARD_ALERT 0 "none" 51 "acc_problem" 55 "cmbs_problem" 75 "key_not_detected" 79 "fasten_seatbelt" 111 "lkas_problem" 131 "brake_system_problem" 132 "brake_hold_problem" 139 "tbd" 161 "door_open";
VAL_ 891 WIPERS 4 "High" 2 "Low" 0 "Off";

VAL_ 399 STEER_STATUS 6 "tmp_fault" 5 "fault_1" 4 "no_torque_alert_2" 3 "low_speed_lockout" 2 "no_torque_alert_1" 0 "normal";

VAL_ 829 BEEP 3 "single_beep" 2 "triple_beep" 1 "repeated_beep" 0 "no_beep";

VAL_ 401 GEAR_SHIFTER 32 "L" 16 "S" 8 "D" 4 "N" 2 "R" 1 "P" ;
VAL_ 401 GEAR 7 "L" 10 "S" 4 "D" 3 "N" 2 "R" 1 "P" ;
VAL_ 545 ECON_ON_2 0 "off" 3 "on" ;
VAL_ 662 CRUISE_BUTTONS 7 "tbd" 6 "tbd" 5 "tbd" 4 "accel_res" 3 "decel_set" 2 "cancel" 1 "main" 0 "none" ;
VAL_ 662 CRUISE_SETTING 3 "distance_adj" 2 "tbd" 1 "lkas_button" 0 "none" ;
